VERSION ""

NS_ :

BS_:

BU_:

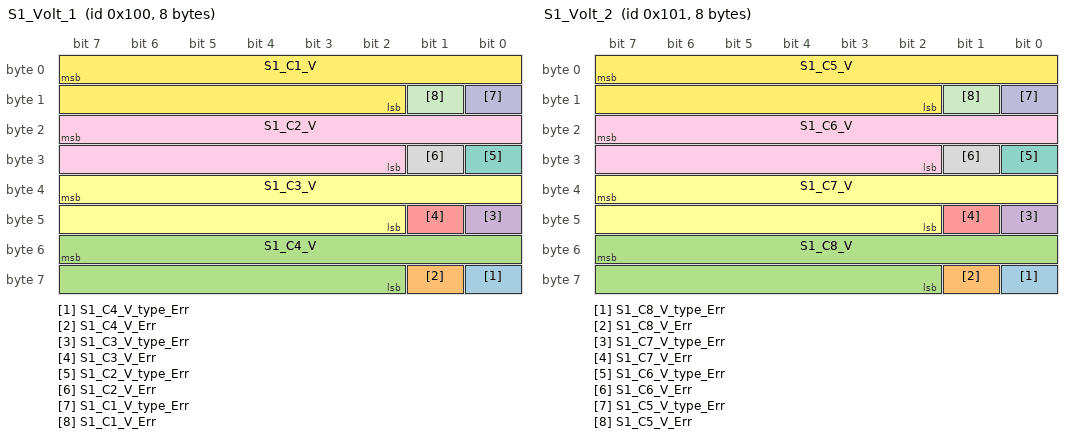
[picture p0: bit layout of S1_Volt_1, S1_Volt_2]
BO_ 256 S1_Volt_1: 8 Master
 SG_ S1_C4_V_type_Err : 56|1@0+ (1,0) [0.0|1.0] "" Vector__XXX
 SG_ S1_C4_V_Err : 57|1@0+ (1,0) [0.0|1.0] "" Vector__XXX
 SG_ S1_C4_V : 55|14@0+ (0.00015,2.3) [2.3|4.75745] "V" Vector__XXX
 SG_ S1_C3_V_type_Err : 40|1@0+ (1,0) [0.0|1.0] "" Vector__XXX
 SG_ S1_C3_V_Err : 41|1@0+ (1,0) [0.0|1.0] "" Vector__XXX
 SG_ S1_C3_V : 39|14@0+ (0.00015,2.3) [2.3|4.75745] "V" Vector__XXX
 SG_ S1_C2_V_type_Err : 24|1@0+ (1,0) [0.0|1.0] "" Vector__XXX
 SG_ S1_C2_V_Err : 25|1@0+ (1,0) [0.0|1.0] "" Vector__XXX
 SG_ S1_C2_V : 23|14@0+ (0.00015,2.3) [2.3|4.75745] "V" Vector__XXX
 SG_ S1_C1_V_type_Err : 8|1@0+ (1,0) [0.0|1.0] "" Vector__XXX
 SG_ S1_C1_V_Err : 9|1@0+ (1,0) [0.0|1.0] "" Vector__XXX
 SG_ S1_C1_V : 7|14@0+ (0.00015,2.3) [2.3|4.75745] "V" Vector__XXX

BO_ 257 S1_Volt_2: 8 Master
 SG_ S1_C8_V_type_Err : 56|1@0+ (1,0) [0.0|1.0] "" Vector__XXX
 SG_ S1_C8_V_Err : 57|1@0+ (1,0) [0.0|1.0] "" Vector__XXX
 SG_ S1_C8_V : 55|14@0+ (0.00015,2.3) [2.3|4.75745] "V" Vector__XXX
 SG_ S1_C7_V_type_Err : 40|1@0+ (1,0) [0.0|1.0] "" Vector__XXX
 SG_ S1_C7_V_Err : 41|1@0+ (1,0) [0.0|1.0] "" Vector__XXX
 SG_ S1_C7_V : 39|14@0+ (0.00015,2.3) [2.3|4.75745] "V" Vector__XXX
 SG_ S1_C6_V_type_Err : 24|1@0+ (1,0) [0.0|1.0] "" Vector__XXX
 SG_ S1_C6_V_Err : 25|1@0+ (1,0) [0.0|1.0] "" Vector__XXX
 SG_ S1_C6_V : 23|14@0+ (0.00015,2.3) [2.3|4.75745] "V" Vector__XXX
 SG_ S1_C5_V_type_Err : 8|1@0+ (1,0) [0.0|1.0] "" Vector__XXX
 SG_ S1_C5_V_Err : 9|1@0+ (1,0) [0.0|1.0] "" Vector__XXX
 SG_ S1_C5_V : 7|14@0+ (0.00015,2.3) [2.3|4.75745] "V" Vector__XXX

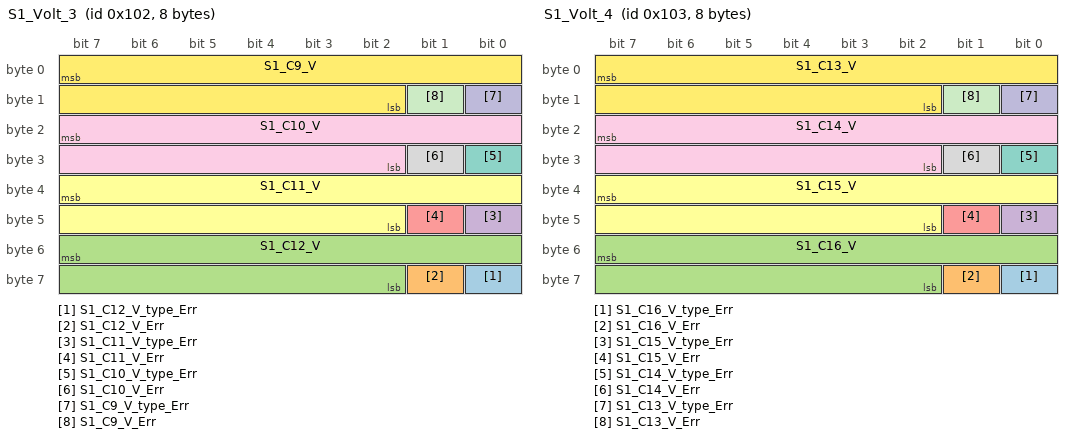
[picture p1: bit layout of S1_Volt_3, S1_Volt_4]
BO_ 258 S1_Volt_3: 8 Master
 SG_ S1_C12_V_type_Err : 56|1@0+ (1,0) [0.0|1.0] "" Vector__XXX
 SG_ S1_C12_V_Err : 57|1@0+ (1,0) [0.0|1.0] "" Vector__XXX
 SG_ S1_C12_V : 55|14@0+ (0.00015,2.3) [2.3|4.75745] "V" Vector__XXX
 SG_ S1_C11_V_type_Err : 40|1@0+ (1,0) [0.0|1.0] "" Vector__XXX
 SG_ S1_C11_V_Err : 41|1@0+ (1,0) [0.0|1.0] "" Vector__XXX
 SG_ S1_C11_V : 39|14@0+ (0.00015,2.3) [2.3|4.75745] "V" Vector__XXX
 SG_ S1_C10_V_type_Err : 24|1@0+ (1,0) [0.0|1.0] "" Vector__XXX
 SG_ S1_C10_V_Err : 25|1@0+ (1,0) [0.0|1.0] "" Vector__XXX
 SG_ S1_C10_V : 23|14@0+ (0.00015,2.3) [2.3|4.75745] "V" Vector__XXX
 SG_ S1_C9_V_type_Err : 8|1@0+ (1,0) [0.0|1.0] "" Vector__XXX
 SG_ S1_C9_V_Err : 9|1@0+ (1,0) [0.0|1.0] "" Vector__XXX
 SG_ S1_C9_V : 7|14@0+ (0.00015,2.3) [2.3|4.75745] "V" Vector__XXX

BO_ 259 S1_Volt_4: 8 Master
 SG_ S1_C16_V_type_Err : 56|1@0+ (1,0) [0.0|1.0] "" Vector__XXX
 SG_ S1_C16_V_Err : 57|1@0+ (1,0) [0.0|1.0] "" Vector__XXX
 SG_ S1_C16_V : 55|14@0+ (0.00015,2.3) [2.3|4.75745] "V" Vector__XXX
 SG_ S1_C15_V_type_Err : 40|1@0+ (1,0) [0.0|1.0] "" Vector__XXX
 SG_ S1_C15_V_Err : 41|1@0+ (1,0) [0.0|1.0] "" Vector__XXX
 SG_ S1_C15_V : 39|14@0+ (0.00015,2.3) [2.3|4.75745] "V" Vector__XXX
 SG_ S1_C14_V_type_Err : 24|1@0+ (1,0) [0.0|1.0] "" Vector__XXX
 SG_ S1_C14_V_Err : 25|1@0+ (1,0) [0.0|1.0] "" Vector__XXX
 SG_ S1_C14_V : 23|14@0+ (0.00015,2.3) [2.3|4.75745] "V" Vector__XXX
 SG_ S1_C13_V_type_Err : 8|1@0+ (1,0) [0.0|1.0] "" Vector__XXX
 SG_ S1_C13_V_Err : 9|1@0+ (1,0) [0.0|1.0] "" Vector__XXX
 SG_ S1_C13_V : 7|14@0+ (0.00015,2.3) [2.3|4.75745] "V" Vector__XXX

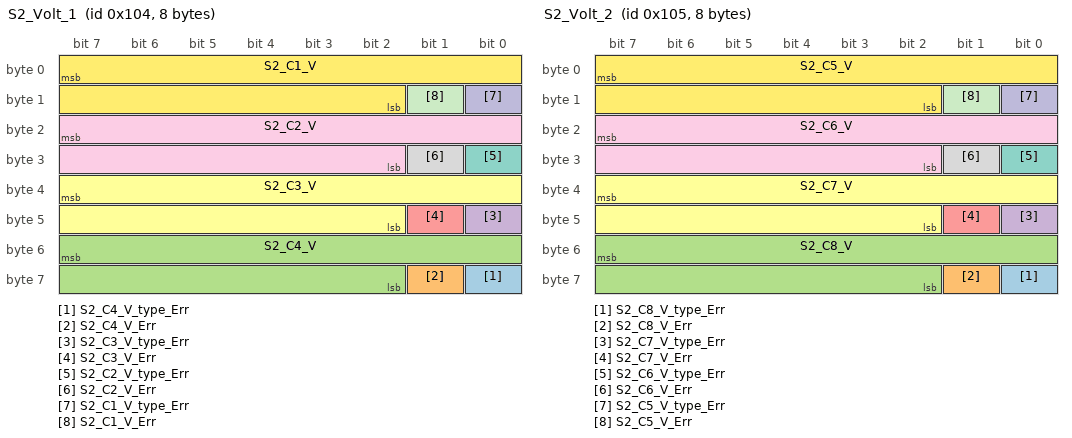
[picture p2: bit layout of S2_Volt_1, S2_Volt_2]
BO_ 260 S2_Volt_1: 8 Master
 SG_ S2_C4_V_type_Err : 56|1@0+ (1,0) [0.0|1.0] "" Vector__XXX
 SG_ S2_C4_V_Err : 57|1@0+ (1,0) [0.0|1.0] "" Vector__XXX
 SG_ S2_C4_V : 55|14@0+ (0.00015,2.3) [2.3|4.75745] "V" Vector__XXX
 SG_ S2_C3_V_type_Err : 40|1@0+ (1,0) [0.0|1.0] "" Vector__XXX
 SG_ S2_C3_V_Err : 41|1@0+ (1,0) [0.0|1.0] "" Vector__XXX
 SG_ S2_C3_V : 39|14@0+ (0.00015,2.3) [2.3|4.75745] "V" Vector__XXX
 SG_ S2_C2_V_type_Err : 24|1@0+ (1,0) [0.0|1.0] "" Vector__XXX
 SG_ S2_C2_V_Err : 25|1@0+ (1,0) [0.0|1.0] "" Vector__XXX
 SG_ S2_C2_V : 23|14@0+ (0.00015,2.3) [2.3|4.75745] "V" Vector__XXX
 SG_ S2_C1_V_type_Err : 8|1@0+ (1,0) [0.0|1.0] "" Vector__XXX
 SG_ S2_C1_V_Err : 9|1@0+ (1,0) [0.0|1.0] "" Vector__XXX
 SG_ S2_C1_V : 7|14@0+ (0.00015,2.3) [2.3|4.75745] "V" Vector__XXX

BO_ 261 S2_Volt_2: 8 Master
 SG_ S2_C8_V_type_Err : 56|1@0+ (1,0) [0.0|1.0] "" Vector__XXX
 SG_ S2_C8_V_Err : 57|1@0+ (1,0) [0.0|1.0] "" Vector__XXX
 SG_ S2_C8_V : 55|14@0+ (0.00015,2.3) [2.3|4.75745] "V" Vector__XXX
 SG_ S2_C7_V_type_Err : 40|1@0+ (1,0) [0.0|1.0] "" Vector__XXX
 SG_ S2_C7_V_Err : 41|1@0+ (1,0) [0.0|1.0] "" Vector__XXX
 SG_ S2_C7_V : 39|14@0+ (0.00015,2.3) [2.3|4.75745] "V" Vector__XXX
 SG_ S2_C6_V_type_Err : 24|1@0+ (1,0) [0.0|1.0] "" Vector__XXX
 SG_ S2_C6_V_Err : 25|1@0+ (1,0) [0.0|1.0] "" Vector__XXX
 SG_ S2_C6_V : 23|14@0+ (0.00015,2.3) [2.3|4.75745] "V" Vector__XXX
 SG_ S2_C5_V_type_Err : 8|1@0+ (1,0) [0.0|1.0] "" Vector__XXX
 SG_ S2_C5_V_Err : 9|1@0+ (1,0) [0.0|1.0] "" Vector__XXX
 SG_ S2_C5_V : 7|14@0+ (0.00015,2.3) [2.3|4.75745] "V" Vector__XXX

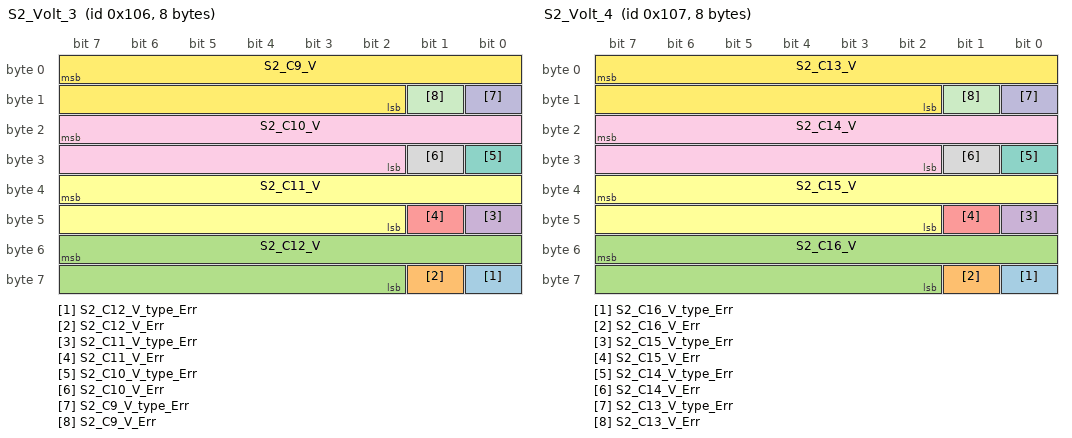
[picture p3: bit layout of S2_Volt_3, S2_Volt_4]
BO_ 262 S2_Volt_3: 8 Master
 SG_ S2_C12_V_type_Err : 56|1@0+ (1,0) [0.0|1.0] "" Vector__XXX
 SG_ S2_C12_V_Err : 57|1@0+ (1,0) [0.0|1.0] "" Vector__XXX
 SG_ S2_C12_V : 55|14@0+ (0.00015,2.3) [2.3|4.75745] "V" Vector__XXX
 SG_ S2_C11_V_type_Err : 40|1@0+ (1,0) [0.0|1.0] "" Vector__XXX
 SG_ S2_C11_V_Err : 41|1@0+ (1,0) [0.0|1.0] "" Vector__XXX
 SG_ S2_C11_V : 39|14@0+ (0.00015,2.3) [2.3|4.75745] "V" Vector__XXX
 SG_ S2_C10_V_type_Err : 24|1@0+ (1,0) [0.0|1.0] "" Vector__XXX
 SG_ S2_C10_V_Err : 25|1@0+ (1,0) [0.0|1.0] "" Vector__XXX
 SG_ S2_C10_V : 23|14@0+ (0.00015,2.3) [2.3|4.75745] "V" Vector__XXX
 SG_ S2_C9_V_type_Err : 8|1@0+ (1,0) [0.0|1.0] "" Vector__XXX
 SG_ S2_C9_V_Err : 9|1@0+ (1,0) [0.0|1.0] "" Vector__XXX
 SG_ S2_C9_V : 7|14@0+ (0.00015,2.3) [2.3|4.75745] "V" Vector__XXX

BO_ 263 S2_Volt_4: 8 Master
 SG_ S2_C16_V_type_Err : 56|1@0+ (1,0) [0.0|1.0] "" Vector__XXX
 SG_ S2_C16_V_Err : 57|1@0+ (1,0) [0.0|1.0] "" Vector__XXX
 SG_ S2_C16_V : 55|14@0+ (0.00015,2.3) [2.3|4.75745] "V" Vector__XXX
 SG_ S2_C15_V_type_Err : 40|1@0+ (1,0) [0.0|1.0] "" Vector__XXX
 SG_ S2_C15_V_Err : 41|1@0+ (1,0) [0.0|1.0] "" Vector__XXX
 SG_ S2_C15_V : 39|14@0+ (0.00015,2.3) [2.3|4.75745] "V" Vector__XXX
 SG_ S2_C14_V_type_Err : 24|1@0+ (1,0) [0.0|1.0] "" Vector__XXX
 SG_ S2_C14_V_Err : 25|1@0+ (1,0) [0.0|1.0] "" Vector__XXX
 SG_ S2_C14_V : 23|14@0+ (0.00015,2.3) [2.3|4.75745] "V" Vector__XXX
 SG_ S2_C13_V_type_Err : 8|1@0+ (1,0) [0.0|1.0] "" Vector__XXX
 SG_ S2_C13_V_Err : 9|1@0+ (1,0) [0.0|1.0] "" Vector__XXX
 SG_ S2_C13_V : 7|14@0+ (0.00015,2.3) [2.3|4.75745] "V" Vector__XXX

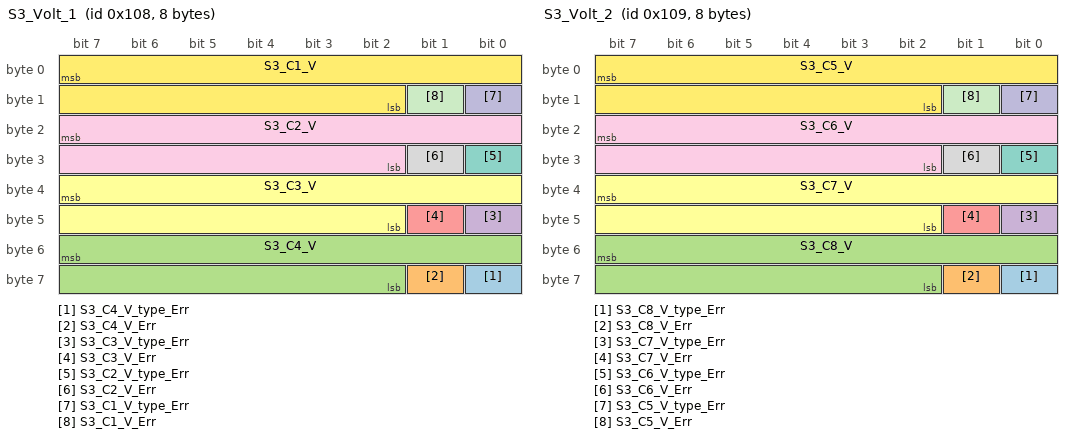
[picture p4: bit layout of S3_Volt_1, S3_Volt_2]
BO_ 264 S3_Volt_1: 8 Master
 SG_ S3_C4_V_type_Err : 56|1@0+ (1,0) [0.0|1.0] "" Vector__XXX
 SG_ S3_C4_V_Err : 57|1@0+ (1,0) [0.0|1.0] "" Vector__XXX
 SG_ S3_C4_V : 55|14@0+ (0.00015,2.3) [2.3|4.75745] "V" Vector__XXX
 SG_ S3_C3_V_type_Err : 40|1@0+ (1,0) [0.0|1.0] "" Vector__XXX
 SG_ S3_C3_V_Err : 41|1@0+ (1,0) [0.0|1.0] "" Vector__XXX
 SG_ S3_C3_V : 39|14@0+ (0.00015,2.3) [2.3|4.75745] "V" Vector__XXX
 SG_ S3_C2_V_type_Err : 24|1@0+ (1,0) [0.0|1.0] "" Vector__XXX
 SG_ S3_C2_V_Err : 25|1@0+ (1,0) [0.0|1.0] "" Vector__XXX
 SG_ S3_C2_V : 23|14@0+ (0.00015,2.3) [2.3|4.75745] "V" Vector__XXX
 SG_ S3_C1_V_type_Err : 8|1@0+ (1,0) [0.0|1.0] "" Vector__XXX
 SG_ S3_C1_V_Err : 9|1@0+ (1,0) [0.0|1.0] "" Vector__XXX
 SG_ S3_C1_V : 7|14@0+ (0.00015,2.3) [2.3|4.75745] "V" Vector__XXX

BO_ 265 S3_Volt_2: 8 Master
 SG_ S3_C8_V_type_Err : 56|1@0+ (1,0) [0.0|1.0] "" Vector__XXX
 SG_ S3_C8_V_Err : 57|1@0+ (1,0) [0.0|1.0] "" Vector__XXX
 SG_ S3_C8_V : 55|14@0+ (0.00015,2.3) [2.3|4.75745] "V" Vector__XXX
 SG_ S3_C7_V_type_Err : 40|1@0+ (1,0) [0.0|1.0] "" Vector__XXX
 SG_ S3_C7_V_Err : 41|1@0+ (1,0) [0.0|1.0] "" Vector__XXX
 SG_ S3_C7_V : 39|14@0+ (0.00015,2.3) [2.3|4.75745] "V" Vector__XXX
 SG_ S3_C6_V_type_Err : 24|1@0+ (1,0) [0.0|1.0] "" Vector__XXX
 SG_ S3_C6_V_Err : 25|1@0+ (1,0) [0.0|1.0] "" Vector__XXX
 SG_ S3_C6_V : 23|14@0+ (0.00015,2.3) [2.3|4.75745] "V" Vector__XXX
 SG_ S3_C5_V_type_Err : 8|1@0+ (1,0) [0.0|1.0] "" Vector__XXX
 SG_ S3_C5_V_Err : 9|1@0+ (1,0) [0.0|1.0] "" Vector__XXX
 SG_ S3_C5_V : 7|14@0+ (0.00015,2.3) [2.3|4.75745] "V" Vector__XXX

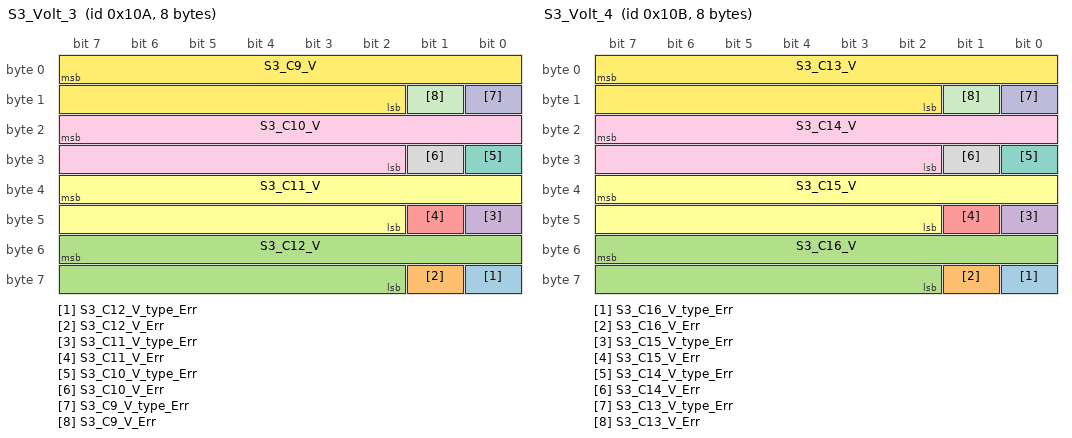
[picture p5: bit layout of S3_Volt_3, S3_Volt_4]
BO_ 266 S3_Volt_3: 8 Master
 SG_ S3_C12_V_type_Err : 56|1@0+ (1,0) [0.0|1.0] "" Vector__XXX
 SG_ S3_C12_V_Err : 57|1@0+ (1,0) [0.0|1.0] "" Vector__XXX
 SG_ S3_C12_V : 55|14@0+ (0.00015,2.3) [2.3|4.75745] "V" Vector__XXX
 SG_ S3_C11_V_type_Err : 40|1@0+ (1,0) [0.0|1.0] "" Vector__XXX
 SG_ S3_C11_V_Err : 41|1@0+ (1,0) [0.0|1.0] "" Vector__XXX
 SG_ S3_C11_V : 39|14@0+ (0.00015,2.3) [2.3|4.75745] "V" Vector__XXX
 SG_ S3_C10_V_type_Err : 24|1@0+ (1,0) [0.0|1.0] "" Vector__XXX
 SG_ S3_C10_V_Err : 25|1@0+ (1,0) [0.0|1.0] "" Vector__XXX
 SG_ S3_C10_V : 23|14@0+ (0.00015,2.3) [2.3|4.75745] "V" Vector__XXX
 SG_ S3_C9_V_type_Err : 8|1@0+ (1,0) [0.0|1.0] "" Vector__XXX
 SG_ S3_C9_V_Err : 9|1@0+ (1,0) [0.0|1.0] "" Vector__XXX
 SG_ S3_C9_V : 7|14@0+ (0.00015,2.3) [2.3|4.75745] "V" Vector__XXX

BO_ 267 S3_Volt_4: 8 Master
 SG_ S3_C16_V_type_Err : 56|1@0+ (1,0) [0.0|1.0] "" Vector__XXX
 SG_ S3_C16_V_Err : 57|1@0+ (1,0) [0.0|1.0] "" Vector__XXX
 SG_ S3_C16_V : 55|14@0+ (0.00015,2.3) [2.3|4.75745] "V" Vector__XXX
 SG_ S3_C15_V_type_Err : 40|1@0+ (1,0) [0.0|1.0] "" Vector__XXX
 SG_ S3_C15_V_Err : 41|1@0+ (1,0) [0.0|1.0] "" Vector__XXX
 SG_ S3_C15_V : 39|14@0+ (0.00015,2.3) [2.3|4.75745] "V" Vector__XXX
 SG_ S3_C14_V_type_Err : 24|1@0+ (1,0) [0.0|1.0] "" Vector__XXX
 SG_ S3_C14_V_Err : 25|1@0+ (1,0) [0.0|1.0] "" Vector__XXX
 SG_ S3_C14_V : 23|14@0+ (0.00015,2.3) [2.3|4.75745] "V" Vector__XXX
 SG_ S3_C13_V_type_Err : 8|1@0+ (1,0) [0.0|1.0] "" Vector__XXX
 SG_ S3_C13_V_Err : 9|1@0+ (1,0) [0.0|1.0] "" Vector__XXX
 SG_ S3_C13_V : 7|14@0+ (0.00015,2.3) [2.3|4.75745] "V" Vector__XXX

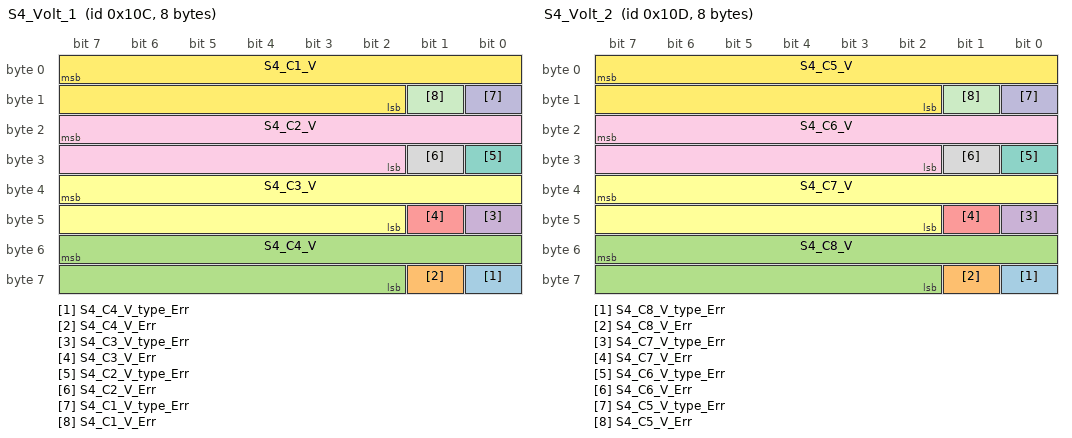
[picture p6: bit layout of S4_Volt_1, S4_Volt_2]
BO_ 268 S4_Volt_1: 8 Master
 SG_ S4_C4_V_type_Err : 56|1@0+ (1,0) [0.0|1.0] "" Vector__XXX
 SG_ S4_C4_V_Err : 57|1@0+ (1,0) [0.0|1.0] "" Vector__XXX
 SG_ S4_C4_V : 55|14@0+ (0.00015,2.3) [2.3|4.75745] "V" Vector__XXX
 SG_ S4_C3_V_type_Err : 40|1@0+ (1,0) [0.0|1.0] "" Vector__XXX
 SG_ S4_C3_V_Err : 41|1@0+ (1,0) [0.0|1.0] "" Vector__XXX
 SG_ S4_C3_V : 39|14@0+ (0.00015,2.3) [2.3|4.75745] "V" Vector__XXX
 SG_ S4_C2_V_type_Err : 24|1@0+ (1,0) [0.0|1.0] "" Vector__XXX
 SG_ S4_C2_V_Err : 25|1@0+ (1,0) [0.0|1.0] "" Vector__XXX
 SG_ S4_C2_V : 23|14@0+ (0.00015,2.3) [2.3|4.75745] "V" Vector__XXX
 SG_ S4_C1_V_type_Err : 8|1@0+ (1,0) [0.0|1.0] "" Vector__XXX
 SG_ S4_C1_V_Err : 9|1@0+ (1,0) [0.0|1.0] "" Vector__XXX
 SG_ S4_C1_V : 7|14@0+ (0.00015,2.3) [2.3|4.75745] "V" Vector__XXX

BO_ 269 S4_Volt_2: 8 Master
 SG_ S4_C8_V_type_Err : 56|1@0+ (1,0) [0.0|1.0] "" Vector__XXX
 SG_ S4_C8_V_Err : 57|1@0+ (1,0) [0.0|1.0] "" Vector__XXX
 SG_ S4_C8_V : 55|14@0+ (0.00015,2.3) [2.3|4.75745] "V" Vector__XXX
 SG_ S4_C7_V_type_Err : 40|1@0+ (1,0) [0.0|1.0] "" Vector__XXX
 SG_ S4_C7_V_Err : 41|1@0+ (1,0) [0.0|1.0] "" Vector__XXX
 SG_ S4_C7_V : 39|14@0+ (0.00015,2.3) [2.3|4.75745] "V" Vector__XXX
 SG_ S4_C6_V_type_Err : 24|1@0+ (1,0) [0.0|1.0] "" Vector__XXX
 SG_ S4_C6_V_Err : 25|1@0+ (1,0) [0.0|1.0] "" Vector__XXX
 SG_ S4_C6_V : 23|14@0+ (0.00015,2.3) [2.3|4.75745] "V" Vector__XXX
 SG_ S4_C5_V_type_Err : 8|1@0+ (1,0) [0.0|1.0] "" Vector__XXX
 SG_ S4_C5_V_Err : 9|1@0+ (1,0) [0.0|1.0] "" Vector__XXX
 SG_ S4_C5_V : 7|14@0+ (0.00015,2.3) [2.3|4.75745] "V" Vector__XXX

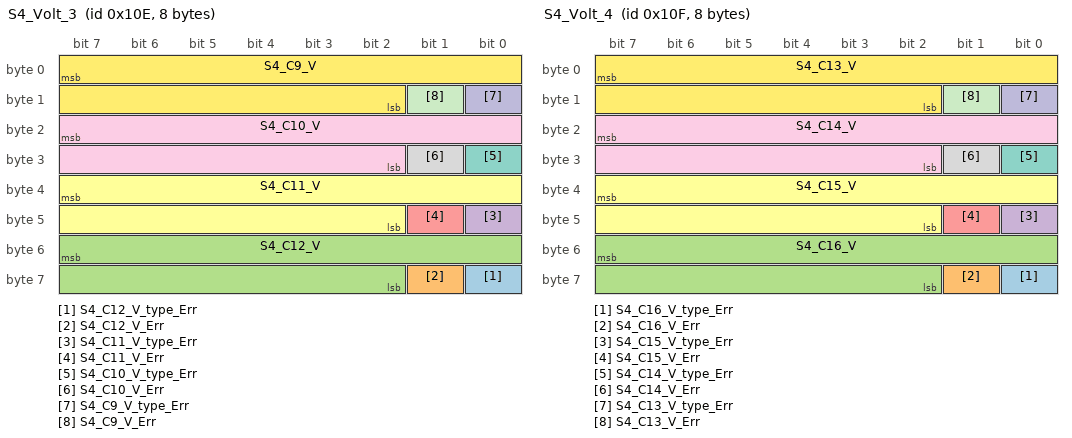
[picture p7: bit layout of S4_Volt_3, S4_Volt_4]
BO_ 270 S4_Volt_3: 8 Master
 SG_ S4_C12_V_type_Err : 56|1@0+ (1,0) [0.0|1.0] "" Vector__XXX
 SG_ S4_C12_V_Err : 57|1@0+ (1,0) [0.0|1.0] "" Vector__XXX
 SG_ S4_C12_V : 55|14@0+ (0.00015,2.3) [2.3|4.75745] "V" Vector__XXX
 SG_ S4_C11_V_type_Err : 40|1@0+ (1,0) [0.0|1.0] "" Vector__XXX
 SG_ S4_C11_V_Err : 41|1@0+ (1,0) [0.0|1.0] "" Vector__XXX
 SG_ S4_C11_V : 39|14@0+ (0.00015,2.3) [2.3|4.75745] "V" Vector__XXX
 SG_ S4_C10_V_type_Err : 24|1@0+ (1,0) [0.0|1.0] "" Vector__XXX
 SG_ S4_C10_V_Err : 25|1@0+ (1,0) [0.0|1.0] "" Vector__XXX
 SG_ S4_C10_V : 23|14@0+ (0.00015,2.3) [2.3|4.75745] "V" Vector__XXX
 SG_ S4_C9_V_type_Err : 8|1@0+ (1,0) [0.0|1.0] "" Vector__XXX
 SG_ S4_C9_V_Err : 9|1@0+ (1,0) [0.0|1.0] "" Vector__XXX
 SG_ S4_C9_V : 7|14@0+ (0.00015,2.3) [2.3|4.75745] "V" Vector__XXX

BO_ 271 S4_Volt_4: 8 Master
 SG_ S4_C16_V_type_Err : 56|1@0+ (1,0) [0.0|1.0] "" Vector__XXX
 SG_ S4_C16_V_Err : 57|1@0+ (1,0) [0.0|1.0] "" Vector__XXX
 SG_ S4_C16_V : 55|14@0+ (0.00015,2.3) [2.3|4.75745] "V" Vector__XXX
 SG_ S4_C15_V_type_Err : 40|1@0+ (1,0) [0.0|1.0] "" Vector__XXX
 SG_ S4_C15_V_Err : 41|1@0+ (1,0) [0.0|1.0] "" Vector__XXX
 SG_ S4_C15_V : 39|14@0+ (0.00015,2.3) [2.3|4.75745] "V" Vector__XXX
 SG_ S4_C14_V_type_Err : 24|1@0+ (1,0) [0.0|1.0] "" Vector__XXX
 SG_ S4_C14_V_Err : 25|1@0+ (1,0) [0.0|1.0] "" Vector__XXX
 SG_ S4_C14_V : 23|14@0+ (0.00015,2.3) [2.3|4.75745] "V" Vector__XXX
 SG_ S4_C13_V_type_Err : 8|1@0+ (1,0) [0.0|1.0] "" Vector__XXX
 SG_ S4_C13_V_Err : 9|1@0+ (1,0) [0.0|1.0] "" Vector__XXX
 SG_ S4_C13_V : 7|14@0+ (0.00015,2.3) [2.3|4.75745] "V" Vector__XXX

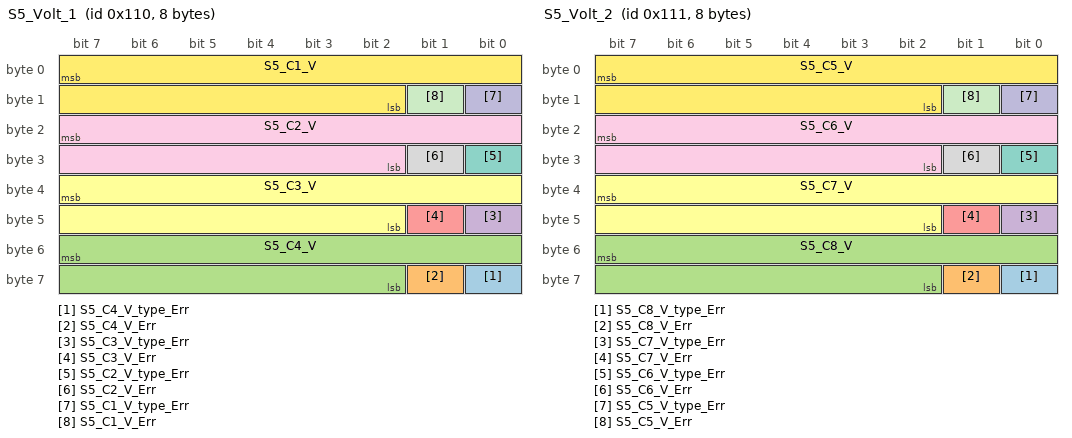
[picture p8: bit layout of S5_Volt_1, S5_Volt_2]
BO_ 272 S5_Volt_1: 8 Master
 SG_ S5_C4_V_type_Err : 56|1@0+ (1,0) [0.0|1.0] "" Vector__XXX
 SG_ S5_C4_V_Err : 57|1@0+ (1,0) [0.0|1.0] "" Vector__XXX
 SG_ S5_C4_V : 55|14@0+ (0.00015,2.3) [2.3|4.75745] "V" Vector__XXX
 SG_ S5_C3_V_type_Err : 40|1@0+ (1,0) [0.0|1.0] "" Vector__XXX
 SG_ S5_C3_V_Err : 41|1@0+ (1,0) [0.0|1.0] "" Vector__XXX
 SG_ S5_C3_V : 39|14@0+ (0.00015,2.3) [2.3|4.75745] "V" Vector__XXX
 SG_ S5_C2_V_type_Err : 24|1@0+ (1,0) [0.0|1.0] "" Vector__XXX
 SG_ S5_C2_V_Err : 25|1@0+ (1,0) [0.0|1.0] "" Vector__XXX
 SG_ S5_C2_V : 23|14@0+ (0.00015,2.3) [2.3|4.75745] "V" Vector__XXX
 SG_ S5_C1_V_type_Err : 8|1@0+ (1,0) [0.0|1.0] "" Vector__XXX
 SG_ S5_C1_V_Err : 9|1@0+ (1,0) [0.0|1.0] "" Vector__XXX
 SG_ S5_C1_V : 7|14@0+ (0.00015,2.3) [2.3|4.75745] "V" Vector__XXX

BO_ 273 S5_Volt_2: 8 Master
 SG_ S5_C8_V_type_Err : 56|1@0+ (1,0) [0.0|1.0] "" Vector__XXX
 SG_ S5_C8_V_Err : 57|1@0+ (1,0) [0.0|1.0] "" Vector__XXX
 SG_ S5_C8_V : 55|14@0+ (0.00015,2.3) [2.3|4.75745] "V" Vector__XXX
 SG_ S5_C7_V_type_Err : 40|1@0+ (1,0) [0.0|1.0] "" Vector__XXX
 SG_ S5_C7_V_Err : 41|1@0+ (1,0) [0.0|1.0] "" Vector__XXX
 SG_ S5_C7_V : 39|14@0+ (0.00015,2.3) [2.3|4.75745] "V" Vector__XXX
 SG_ S5_C6_V_type_Err : 24|1@0+ (1,0) [0.0|1.0] "" Vector__XXX
 SG_ S5_C6_V_Err : 25|1@0+ (1,0) [0.0|1.0] "" Vector__XXX
 SG_ S5_C6_V : 23|14@0+ (0.00015,2.3) [2.3|4.75745] "V" Vector__XXX
 SG_ S5_C5_V_type_Err : 8|1@0+ (1,0) [0.0|1.0] "" Vector__XXX
 SG_ S5_C5_V_Err : 9|1@0+ (1,0) [0.0|1.0] "" Vector__XXX
 SG_ S5_C5_V : 7|14@0+ (0.00015,2.3) [2.3|4.75745] "V" Vector__XXX

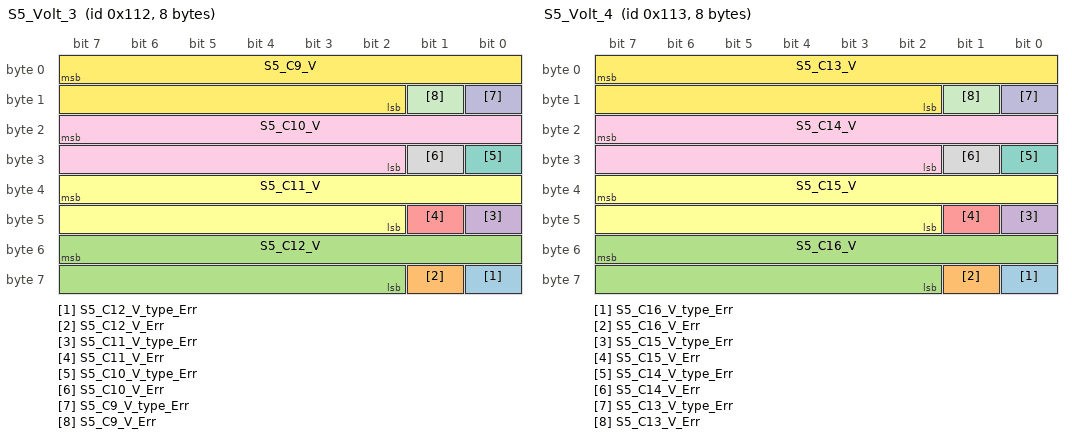
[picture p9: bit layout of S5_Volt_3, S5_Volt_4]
BO_ 274 S5_Volt_3: 8 Master
 SG_ S5_C12_V_type_Err : 56|1@0+ (1,0) [0.0|1.0] "" Vector__XXX
 SG_ S5_C12_V_Err : 57|1@0+ (1,0) [0.0|1.0] "" Vector__XXX
 SG_ S5_C12_V : 55|14@0+ (0.00015,2.3) [2.3|4.75745] "V" Vector__XXX
 SG_ S5_C11_V_type_Err : 40|1@0+ (1,0) [0.0|1.0] "" Vector__XXX
 SG_ S5_C11_V_Err : 41|1@0+ (1,0) [0.0|1.0] "" Vector__XXX
 SG_ S5_C11_V : 39|14@0+ (0.00015,2.3) [2.3|4.75745] "V" Vector__XXX
 SG_ S5_C10_V_type_Err : 24|1@0+ (1,0) [0.0|1.0] "" Vector__XXX
 SG_ S5_C10_V_Err : 25|1@0+ (1,0) [0.0|1.0] "" Vector__XXX
 SG_ S5_C10_V : 23|14@0+ (0.00015,2.3) [2.3|4.75745] "V" Vector__XXX
 SG_ S5_C9_V_type_Err : 8|1@0+ (1,0) [0.0|1.0] "" Vector__XXX
 SG_ S5_C9_V_Err : 9|1@0+ (1,0) [0.0|1.0] "" Vector__XXX
 SG_ S5_C9_V : 7|14@0+ (0.00015,2.3) [2.3|4.75745] "V" Vector__XXX

BO_ 275 S5_Volt_4: 8 Master
 SG_ S5_C16_V_type_Err : 56|1@0+ (1,0) [0.0|1.0] "" Vector__XXX
 SG_ S5_C16_V_Err : 57|1@0+ (1,0) [0.0|1.0] "" Vector__XXX
 SG_ S5_C16_V : 55|14@0+ (0.00015,2.3) [2.3|4.75745] "V" Vector__XXX
 SG_ S5_C15_V_type_Err : 40|1@0+ (1,0) [0.0|1.0] "" Vector__XXX
 SG_ S5_C15_V_Err : 41|1@0+ (1,0) [0.0|1.0] "" Vector__XXX
 SG_ S5_C15_V : 39|14@0+ (0.00015,2.3) [2.3|4.75745] "V" Vector__XXX
 SG_ S5_C14_V_type_Err : 24|1@0+ (1,0) [0.0|1.0] "" Vector__XXX
 SG_ S5_C14_V_Err : 25|1@0+ (1,0) [0.0|1.0] "" Vector__XXX
 SG_ S5_C14_V : 23|14@0+ (0.00015,2.3) [2.3|4.75745] "V" Vector__XXX
 SG_ S5_C13_V_type_Err : 8|1@0+ (1,0) [0.0|1.0] "" Vector__XXX
 SG_ S5_C13_V_Err : 9|1@0+ (1,0) [0.0|1.0] "" Vector__XXX
 SG_ S5_C13_V : 7|14@0+ (0.00015,2.3) [2.3|4.75745] "V" Vector__XXX

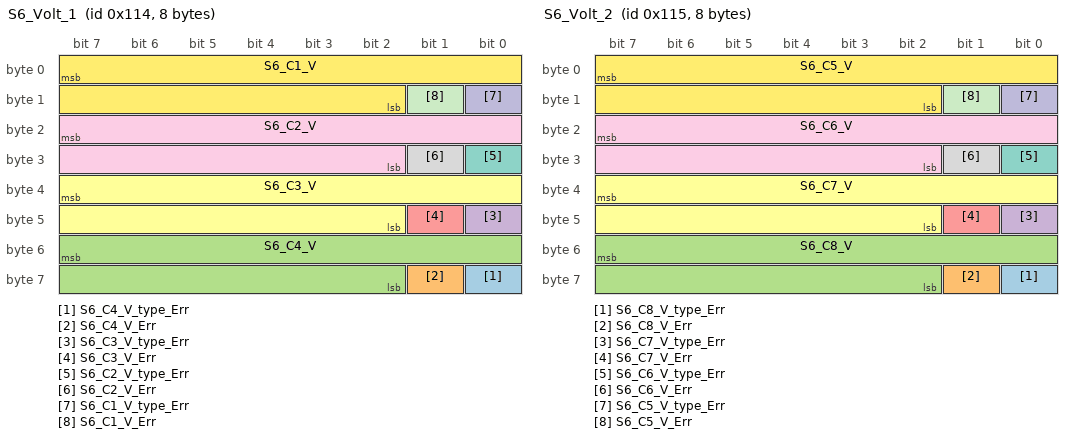
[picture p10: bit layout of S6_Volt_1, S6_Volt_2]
BO_ 276 S6_Volt_1: 8 Master
 SG_ S6_C4_V_type_Err : 56|1@0+ (1,0) [0.0|1.0] "" Vector__XXX
 SG_ S6_C4_V_Err : 57|1@0+ (1,0) [0.0|1.0] "" Vector__XXX
 SG_ S6_C4_V : 55|14@0+ (0.00015,2.3) [2.3|4.75745] "V" Vector__XXX
 SG_ S6_C3_V_type_Err : 40|1@0+ (1,0) [0.0|1.0] "" Vector__XXX
 SG_ S6_C3_V_Err : 41|1@0+ (1,0) [0.0|1.0] "" Vector__XXX
 SG_ S6_C3_V : 39|14@0+ (0.00015,2.3) [2.3|4.75745] "V" Vector__XXX
 SG_ S6_C2_V_type_Err : 24|1@0+ (1,0) [0.0|1.0] "" Vector__XXX
 SG_ S6_C2_V_Err : 25|1@0+ (1,0) [0.0|1.0] "" Vector__XXX
 SG_ S6_C2_V : 23|14@0+ (0.00015,2.3) [2.3|4.75745] "V" Vector__XXX
 SG_ S6_C1_V_type_Err : 8|1@0+ (1,0) [0.0|1.0] "" Vector__XXX
 SG_ S6_C1_V_Err : 9|1@0+ (1,0) [0.0|1.0] "" Vector__XXX
 SG_ S6_C1_V : 7|14@0+ (0.00015,2.3) [2.3|4.75745] "V" Vector__XXX

BO_ 277 S6_Volt_2: 8 Master
 SG_ S6_C8_V_type_Err : 56|1@0+ (1,0) [0.0|1.0] "" Vector__XXX
 SG_ S6_C8_V_Err : 57|1@0+ (1,0) [0.0|1.0] "" Vector__XXX
 SG_ S6_C8_V : 55|14@0+ (0.00015,2.3) [2.3|4.75745] "V" Vector__XXX
 SG_ S6_C7_V_type_Err : 40|1@0+ (1,0) [0.0|1.0] "" Vector__XXX
 SG_ S6_C7_V_Err : 41|1@0+ (1,0) [0.0|1.0] "" Vector__XXX
 SG_ S6_C7_V : 39|14@0+ (0.00015,2.3) [2.3|4.75745] "V" Vector__XXX
 SG_ S6_C6_V_type_Err : 24|1@0+ (1,0) [0.0|1.0] "" Vector__XXX
 SG_ S6_C6_V_Err : 25|1@0+ (1,0) [0.0|1.0] "" Vector__XXX
 SG_ S6_C6_V : 23|14@0+ (0.00015,2.3) [2.3|4.75745] "V" Vector__XXX
 SG_ S6_C5_V_type_Err : 8|1@0+ (1,0) [0.0|1.0] "" Vector__XXX
 SG_ S6_C5_V_Err : 9|1@0+ (1,0) [0.0|1.0] "" Vector__XXX
 SG_ S6_C5_V : 7|14@0+ (0.00015,2.3) [2.3|4.75745] "V" Vector__XXX

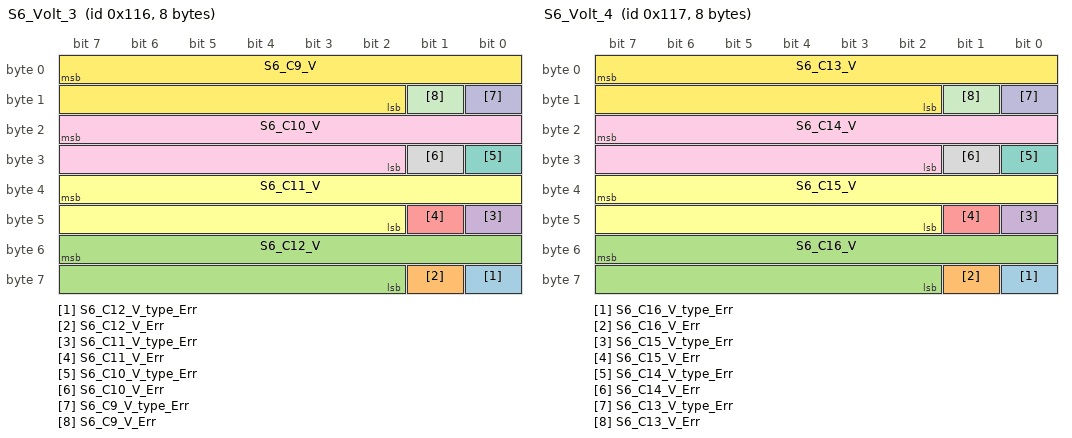
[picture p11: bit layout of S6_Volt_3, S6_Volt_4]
BO_ 278 S6_Volt_3: 8 Master
 SG_ S6_C12_V_type_Err : 56|1@0+ (1,0) [0.0|1.0] "" Vector__XXX
 SG_ S6_C12_V_Err : 57|1@0+ (1,0) [0.0|1.0] "" Vector__XXX
 SG_ S6_C12_V : 55|14@0+ (0.00015,2.3) [2.3|4.75745] "V" Vector__XXX
 SG_ S6_C11_V_type_Err : 40|1@0+ (1,0) [0.0|1.0] "" Vector__XXX
 SG_ S6_C11_V_Err : 41|1@0+ (1,0) [0.0|1.0] "" Vector__XXX
 SG_ S6_C11_V : 39|14@0+ (0.00015,2.3) [2.3|4.75745] "V" Vector__XXX
 SG_ S6_C10_V_type_Err : 24|1@0+ (1,0) [0.0|1.0] "" Vector__XXX
 SG_ S6_C10_V_Err : 25|1@0+ (1,0) [0.0|1.0] "" Vector__XXX
 SG_ S6_C10_V : 23|14@0+ (0.00015,2.3) [2.3|4.75745] "V" Vector__XXX
 SG_ S6_C9_V_type_Err : 8|1@0+ (1,0) [0.0|1.0] "" Vector__XXX
 SG_ S6_C9_V_Err : 9|1@0+ (1,0) [0.0|1.0] "" Vector__XXX
 SG_ S6_C9_V : 7|14@0+ (0.00015,2.3) [2.3|4.75745] "V" Vector__XXX

BO_ 279 S6_Volt_4: 8 Master
 SG_ S6_C16_V_type_Err : 56|1@0+ (1,0) [0.0|1.0] "" Vector__XXX
 SG_ S6_C16_V_Err : 57|1@0+ (1,0) [0.0|1.0] "" Vector__XXX
 SG_ S6_C16_V : 55|14@0+ (0.00015,2.3) [2.3|4.75745] "V" Vector__XXX
 SG_ S6_C15_V_type_Err : 40|1@0+ (1,0) [0.0|1.0] "" Vector__XXX
 SG_ S6_C15_V_Err : 41|1@0+ (1,0) [0.0|1.0] "" Vector__XXX
 SG_ S6_C15_V : 39|14@0+ (0.00015,2.3) [2.3|4.75745] "V" Vector__XXX
 SG_ S6_C14_V_type_Err : 24|1@0+ (1,0) [0.0|1.0] "" Vector__XXX
 SG_ S6_C14_V_Err : 25|1@0+ (1,0) [0.0|1.0] "" Vector__XXX
 SG_ S6_C14_V : 23|14@0+ (0.00015,2.3) [2.3|4.75745] "V" Vector__XXX
 SG_ S6_C13_V_type_Err : 8|1@0+ (1,0) [0.0|1.0] "" Vector__XXX
 SG_ S6_C13_V_Err : 9|1@0+ (1,0) [0.0|1.0] "" Vector__XXX
 SG_ S6_C13_V : 7|14@0+ (0.00015,2.3) [2.3|4.75745] "V" Vector__XXX

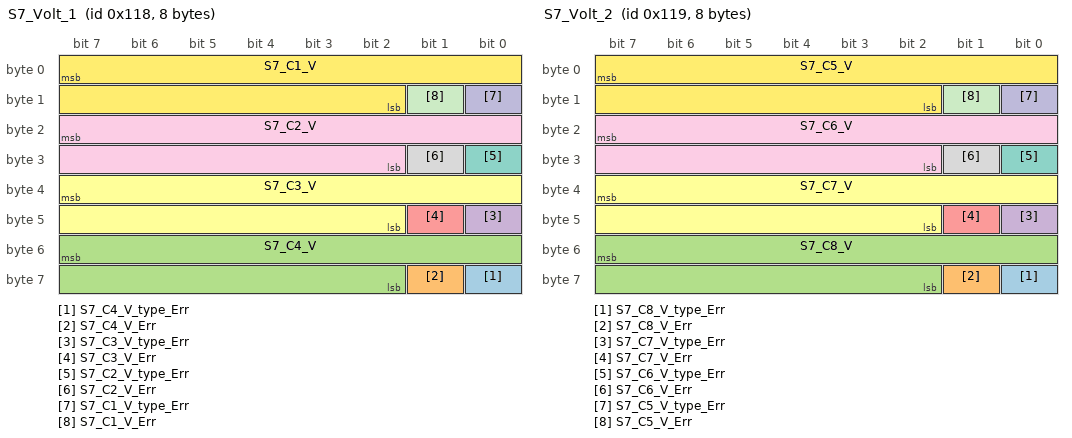
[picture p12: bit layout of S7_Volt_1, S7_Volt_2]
BO_ 280 S7_Volt_1: 8 Master
 SG_ S7_C4_V_type_Err : 56|1@0+ (1,0) [0.0|1.0] "" Vector__XXX
 SG_ S7_C4_V_Err : 57|1@0+ (1,0) [0.0|1.0] "" Vector__XXX
 SG_ S7_C4_V : 55|14@0+ (0.00015,2.3) [2.3|4.75745] "V" Vector__XXX
 SG_ S7_C3_V_type_Err : 40|1@0+ (1,0) [0.0|1.0] "" Vector__XXX
 SG_ S7_C3_V_Err : 41|1@0+ (1,0) [0.0|1.0] "" Vector__XXX
 SG_ S7_C3_V : 39|14@0+ (0.00015,2.3) [2.3|4.75745] "V" Vector__XXX
 SG_ S7_C2_V_type_Err : 24|1@0+ (1,0) [0.0|1.0] "" Vector__XXX
 SG_ S7_C2_V_Err : 25|1@0+ (1,0) [0.0|1.0] "" Vector__XXX
 SG_ S7_C2_V : 23|14@0+ (0.00015,2.3) [2.3|4.75745] "V" Vector__XXX
 SG_ S7_C1_V_type_Err : 8|1@0+ (1,0) [0.0|1.0] "" Vector__XXX
 SG_ S7_C1_V_Err : 9|1@0+ (1,0) [0.0|1.0] "" Vector__XXX
 SG_ S7_C1_V : 7|14@0+ (0.00015,2.3) [2.3|4.75745] "V" Vector__XXX

BO_ 281 S7_Volt_2: 8 Master
 SG_ S7_C8_V_type_Err : 56|1@0+ (1,0) [0.0|1.0] "" Vector__XXX
 SG_ S7_C8_V_Err : 57|1@0+ (1,0) [0.0|1.0] "" Vector__XXX
 SG_ S7_C8_V : 55|14@0+ (0.00015,2.3) [2.3|4.75745] "V" Vector__XXX
 SG_ S7_C7_V_type_Err : 40|1@0+ (1,0) [0.0|1.0] "" Vector__XXX
 SG_ S7_C7_V_Err : 41|1@0+ (1,0) [0.0|1.0] "" Vector__XXX
 SG_ S7_C7_V : 39|14@0+ (0.00015,2.3) [2.3|4.75745] "V" Vector__XXX
 SG_ S7_C6_V_type_Err : 24|1@0+ (1,0) [0.0|1.0] "" Vector__XXX
 SG_ S7_C6_V_Err : 25|1@0+ (1,0) [0.0|1.0] "" Vector__XXX
 SG_ S7_C6_V : 23|14@0+ (0.00015,2.3) [2.3|4.75745] "V" Vector__XXX
 SG_ S7_C5_V_type_Err : 8|1@0+ (1,0) [0.0|1.0] "" Vector__XXX
 SG_ S7_C5_V_Err : 9|1@0+ (1,0) [0.0|1.0] "" Vector__XXX
 SG_ S7_C5_V : 7|14@0+ (0.00015,2.3) [2.3|4.75745] "V" Vector__XXX

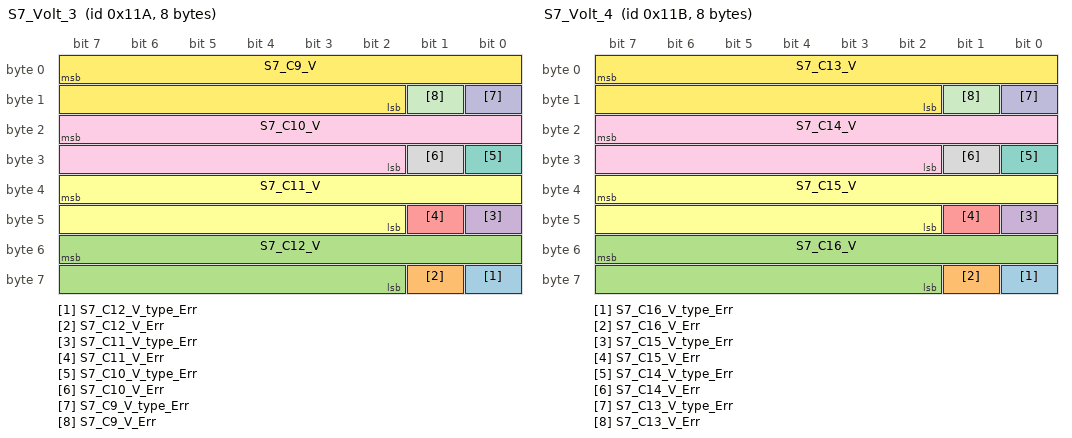
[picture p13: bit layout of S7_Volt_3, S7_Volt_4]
BO_ 282 S7_Volt_3: 8 Master
 SG_ S7_C12_V_type_Err : 56|1@0+ (1,0) [0.0|1.0] "" Vector__XXX
 SG_ S7_C12_V_Err : 57|1@0+ (1,0) [0.0|1.0] "" Vector__XXX
 SG_ S7_C12_V : 55|14@0+ (0.00015,2.3) [2.3|4.75745] "V" Vector__XXX
 SG_ S7_C11_V_type_Err : 40|1@0+ (1,0) [0.0|1.0] "" Vector__XXX
 SG_ S7_C11_V_Err : 41|1@0+ (1,0) [0.0|1.0] "" Vector__XXX
 SG_ S7_C11_V : 39|14@0+ (0.00015,2.3) [2.3|4.75745] "V" Vector__XXX
 SG_ S7_C10_V_type_Err : 24|1@0+ (1,0) [0.0|1.0] "" Vector__XXX
 SG_ S7_C10_V_Err : 25|1@0+ (1,0) [0.0|1.0] "" Vector__XXX
 SG_ S7_C10_V : 23|14@0+ (0.00015,2.3) [2.3|4.75745] "V" Vector__XXX
 SG_ S7_C9_V_type_Err : 8|1@0+ (1,0) [0.0|1.0] "" Vector__XXX
 SG_ S7_C9_V_Err : 9|1@0+ (1,0) [0.0|1.0] "" Vector__XXX
 SG_ S7_C9_V : 7|14@0+ (0.00015,2.3) [2.3|4.75745] "V" Vector__XXX

BO_ 283 S7_Volt_4: 8 Master
 SG_ S7_C16_V_type_Err : 56|1@0+ (1,0) [0.0|1.0] "" Vector__XXX
 SG_ S7_C16_V_Err : 57|1@0+ (1,0) [0.0|1.0] "" Vector__XXX
 SG_ S7_C16_V : 55|14@0+ (0.00015,2.3) [2.3|4.75745] "V" Vector__XXX
 SG_ S7_C15_V_type_Err : 40|1@0+ (1,0) [0.0|1.0] "" Vector__XXX
 SG_ S7_C15_V_Err : 41|1@0+ (1,0) [0.0|1.0] "" Vector__XXX
 SG_ S7_C15_V : 39|14@0+ (0.00015,2.3) [2.3|4.75745] "V" Vector__XXX
 SG_ S7_C14_V_type_Err : 24|1@0+ (1,0) [0.0|1.0] "" Vector__XXX
 SG_ S7_C14_V_Err : 25|1@0+ (1,0) [0.0|1.0] "" Vector__XXX
 SG_ S7_C14_V : 23|14@0+ (0.00015,2.3) [2.3|4.75745] "V" Vector__XXX
 SG_ S7_C13_V_type_Err : 8|1@0+ (1,0) [0.0|1.0] "" Vector__XXX
 SG_ S7_C13_V_Err : 9|1@0+ (1,0) [0.0|1.0] "" Vector__XXX
 SG_ S7_C13_V : 7|14@0+ (0.00015,2.3) [2.3|4.75745] "V" Vector__XXX

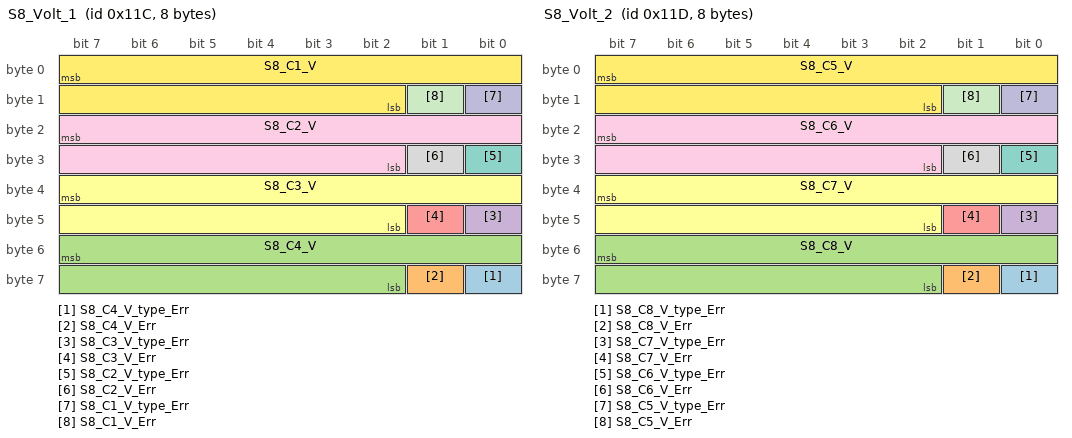
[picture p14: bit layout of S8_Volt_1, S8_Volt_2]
BO_ 284 S8_Volt_1: 8 Master
 SG_ S8_C4_V_type_Err : 56|1@0+ (1,0) [0.0|1.0] "" Vector__XXX
 SG_ S8_C4_V_Err : 57|1@0+ (1,0) [0.0|1.0] "" Vector__XXX
 SG_ S8_C4_V : 55|14@0+ (0.00015,2.3) [2.3|4.75745] "V" Vector__XXX
 SG_ S8_C3_V_type_Err : 40|1@0+ (1,0) [0.0|1.0] "" Vector__XXX
 SG_ S8_C3_V_Err : 41|1@0+ (1,0) [0.0|1.0] "" Vector__XXX
 SG_ S8_C3_V : 39|14@0+ (0.00015,2.3) [2.3|4.75745] "V" Vector__XXX
 SG_ S8_C2_V_type_Err : 24|1@0+ (1,0) [0.0|1.0] "" Vector__XXX
 SG_ S8_C2_V_Err : 25|1@0+ (1,0) [0.0|1.0] "" Vector__XXX
 SG_ S8_C2_V : 23|14@0+ (0.00015,2.3) [2.3|4.75745] "V" Vector__XXX
 SG_ S8_C1_V_type_Err : 8|1@0+ (1,0) [0.0|1.0] "" Vector__XXX
 SG_ S8_C1_V_Err : 9|1@0+ (1,0) [0.0|1.0] "" Vector__XXX
 SG_ S8_C1_V : 7|14@0+ (0.00015,2.3) [2.3|4.75745] "V" Vector__XXX

BO_ 285 S8_Volt_2: 8 Master
 SG_ S8_C8_V_type_Err : 56|1@0+ (1,0) [0.0|1.0] "" Vector__XXX
 SG_ S8_C8_V_Err : 57|1@0+ (1,0) [0.0|1.0] "" Vector__XXX
 SG_ S8_C8_V : 55|14@0+ (0.00015,2.3) [2.3|4.75745] "V" Vector__XXX
 SG_ S8_C7_V_type_Err : 40|1@0+ (1,0) [0.0|1.0] "" Vector__XXX
 SG_ S8_C7_V_Err : 41|1@0+ (1,0) [0.0|1.0] "" Vector__XXX
 SG_ S8_C7_V : 39|14@0+ (0.00015,2.3) [2.3|4.75745] "V" Vector__XXX
 SG_ S8_C6_V_type_Err : 24|1@0+ (1,0) [0.0|1.0] "" Vector__XXX
 SG_ S8_C6_V_Err : 25|1@0+ (1,0) [0.0|1.0] "" Vector__XXX
 SG_ S8_C6_V : 23|14@0+ (0.00015,2.3) [2.3|4.75745] "V" Vector__XXX
 SG_ S8_C5_V_type_Err : 8|1@0+ (1,0) [0.0|1.0] "" Vector__XXX
 SG_ S8_C5_V_Err : 9|1@0+ (1,0) [0.0|1.0] "" Vector__XXX
 SG_ S8_C5_V : 7|14@0+ (0.00015,2.3) [2.3|4.75745] "V" Vector__XXX

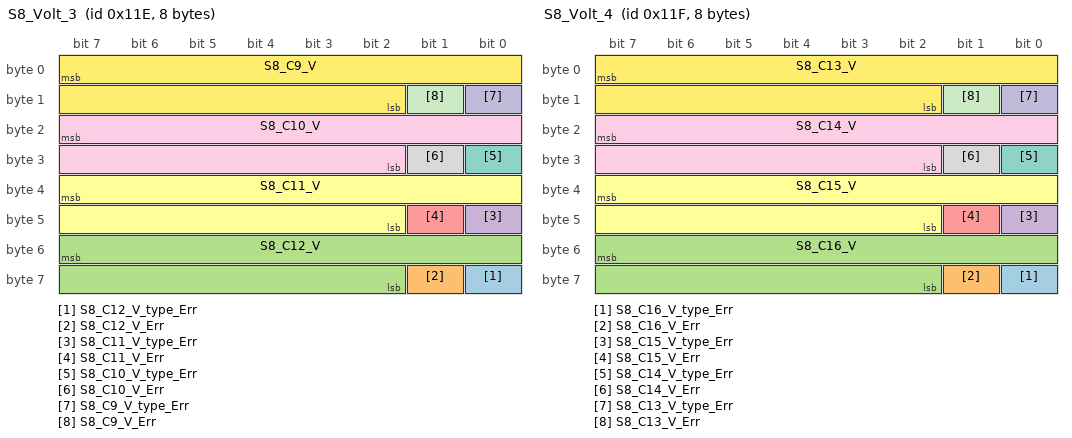
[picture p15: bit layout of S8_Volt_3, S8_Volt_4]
BO_ 286 S8_Volt_3: 8 Master
 SG_ S8_C12_V_type_Err : 56|1@0+ (1,0) [0.0|1.0] "" Vector__XXX
 SG_ S8_C12_V_Err : 57|1@0+ (1,0) [0.0|1.0] "" Vector__XXX
 SG_ S8_C12_V : 55|14@0+ (0.00015,2.3) [2.3|4.75745] "V" Vector__XXX
 SG_ S8_C11_V_type_Err : 40|1@0+ (1,0) [0.0|1.0] "" Vector__XXX
 SG_ S8_C11_V_Err : 41|1@0+ (1,0) [0.0|1.0] "" Vector__XXX
 SG_ S8_C11_V : 39|14@0+ (0.00015,2.3) [2.3|4.75745] "V" Vector__XXX
 SG_ S8_C10_V_type_Err : 24|1@0+ (1,0) [0.0|1.0] "" Vector__XXX
 SG_ S8_C10_V_Err : 25|1@0+ (1,0) [0.0|1.0] "" Vector__XXX
 SG_ S8_C10_V : 23|14@0+ (0.00015,2.3) [2.3|4.75745] "V" Vector__XXX
 SG_ S8_C9_V_type_Err : 8|1@0+ (1,0) [0.0|1.0] "" Vector__XXX
 SG_ S8_C9_V_Err : 9|1@0+ (1,0) [0.0|1.0] "" Vector__XXX
 SG_ S8_C9_V : 7|14@0+ (0.00015,2.3) [2.3|4.75745] "V" Vector__XXX

BO_ 287 S8_Volt_4: 8 Master
 SG_ S8_C16_V_type_Err : 56|1@0+ (1,0) [0.0|1.0] "" Vector__XXX
 SG_ S8_C16_V_Err : 57|1@0+ (1,0) [0.0|1.0] "" Vector__XXX
 SG_ S8_C16_V : 55|14@0+ (0.00015,2.3) [2.3|4.75745] "V" Vector__XXX
 SG_ S8_C15_V_type_Err : 40|1@0+ (1,0) [0.0|1.0] "" Vector__XXX
 SG_ S8_C15_V_Err : 41|1@0+ (1,0) [0.0|1.0] "" Vector__XXX
 SG_ S8_C15_V : 39|14@0+ (0.00015,2.3) [2.3|4.75745] "V" Vector__XXX
 SG_ S8_C14_V_type_Err : 24|1@0+ (1,0) [0.0|1.0] "" Vector__XXX
 SG_ S8_C14_V_Err : 25|1@0+ (1,0) [0.0|1.0] "" Vector__XXX
 SG_ S8_C14_V : 23|14@0+ (0.00015,2.3) [2.3|4.75745] "V" Vector__XXX
 SG_ S8_C13_V_type_Err : 8|1@0+ (1,0) [0.0|1.0] "" Vector__XXX
 SG_ S8_C13_V_Err : 9|1@0+ (1,0) [0.0|1.0] "" Vector__XXX
 SG_ S8_C13_V : 7|14@0+ (0.00015,2.3) [2.3|4.75745] "V" Vector__XXX

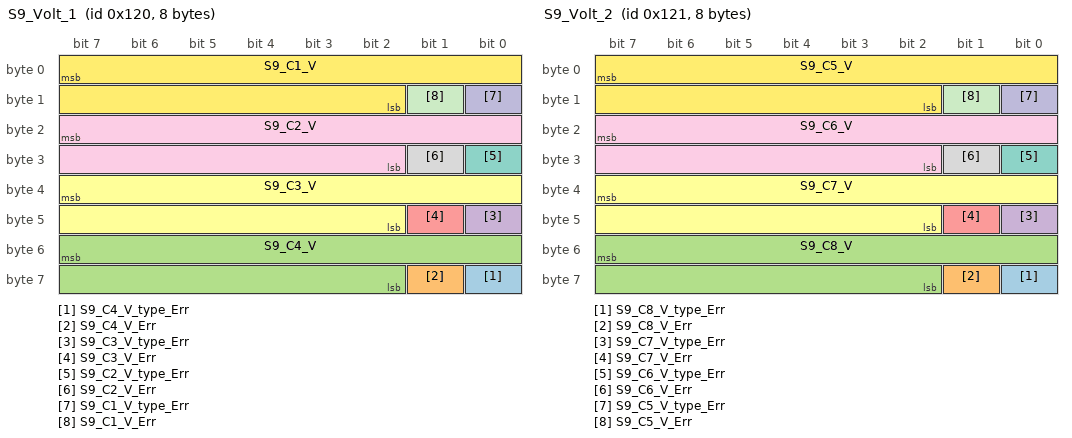
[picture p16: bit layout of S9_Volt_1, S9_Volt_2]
BO_ 288 S9_Volt_1: 8 Master
 SG_ S9_C4_V_type_Err : 56|1@0+ (1,0) [0.0|1.0] "" Vector__XXX
 SG_ S9_C4_V_Err : 57|1@0+ (1,0) [0.0|1.0] "" Vector__XXX
 SG_ S9_C4_V : 55|14@0+ (0.00015,2.3) [2.3|4.75745] "V" Vector__XXX
 SG_ S9_C3_V_type_Err : 40|1@0+ (1,0) [0.0|1.0] "" Vector__XXX
 SG_ S9_C3_V_Err : 41|1@0+ (1,0) [0.0|1.0] "" Vector__XXX
 SG_ S9_C3_V : 39|14@0+ (0.00015,2.3) [2.3|4.75745] "V" Vector__XXX
 SG_ S9_C2_V_type_Err : 24|1@0+ (1,0) [0.0|1.0] "" Vector__XXX
 SG_ S9_C2_V_Err : 25|1@0+ (1,0) [0.0|1.0] "" Vector__XXX
 SG_ S9_C2_V : 23|14@0+ (0.00015,2.3) [2.3|4.75745] "V" Vector__XXX
 SG_ S9_C1_V_type_Err : 8|1@0+ (1,0) [0.0|1.0] "" Vector__XXX
 SG_ S9_C1_V_Err : 9|1@0+ (1,0) [0.0|1.0] "" Vector__XXX
 SG_ S9_C1_V : 7|14@0+ (0.00015,2.3) [2.3|4.75745] "V" Vector__XXX

BO_ 289 S9_Volt_2: 8 Master
 SG_ S9_C8_V_type_Err : 56|1@0+ (1,0) [0.0|1.0] "" Vector__XXX
 SG_ S9_C8_V_Err : 57|1@0+ (1,0) [0.0|1.0] "" Vector__XXX
 SG_ S9_C8_V : 55|14@0+ (0.00015,2.3) [2.3|4.75745] "V" Vector__XXX
 SG_ S9_C7_V_type_Err : 40|1@0+ (1,0) [0.0|1.0] "" Vector__XXX
 SG_ S9_C7_V_Err : 41|1@0+ (1,0) [0.0|1.0] "" Vector__XXX
 SG_ S9_C7_V : 39|14@0+ (0.00015,2.3) [2.3|4.75745] "V" Vector__XXX
 SG_ S9_C6_V_type_Err : 24|1@0+ (1,0) [0.0|1.0] "" Vector__XXX
 SG_ S9_C6_V_Err : 25|1@0+ (1,0) [0.0|1.0] "" Vector__XXX
 SG_ S9_C6_V : 23|14@0+ (0.00015,2.3) [2.3|4.75745] "V" Vector__XXX
 SG_ S9_C5_V_type_Err : 8|1@0+ (1,0) [0.0|1.0] "" Vector__XXX
 SG_ S9_C5_V_Err : 9|1@0+ (1,0) [0.0|1.0] "" Vector__XXX
 SG_ S9_C5_V : 7|14@0+ (0.00015,2.3) [2.3|4.75745] "V" Vector__XXX

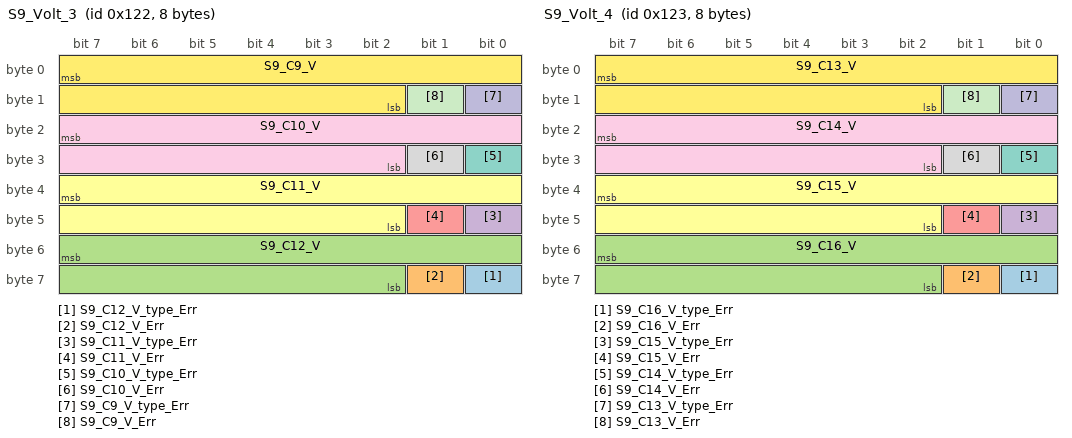
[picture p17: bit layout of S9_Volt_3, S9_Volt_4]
BO_ 290 S9_Volt_3: 8 Master
 SG_ S9_C12_V_type_Err : 56|1@0+ (1,0) [0.0|1.0] "" Vector__XXX
 SG_ S9_C12_V_Err : 57|1@0+ (1,0) [0.0|1.0] "" Vector__XXX
 SG_ S9_C12_V : 55|14@0+ (0.00015,2.3) [2.3|4.75745] "V" Vector__XXX
 SG_ S9_C11_V_type_Err : 40|1@0+ (1,0) [0.0|1.0] "" Vector__XXX
 SG_ S9_C11_V_Err : 41|1@0+ (1,0) [0.0|1.0] "" Vector__XXX
 SG_ S9_C11_V : 39|14@0+ (0.00015,2.3) [2.3|4.75745] "V" Vector__XXX
 SG_ S9_C10_V_type_Err : 24|1@0+ (1,0) [0.0|1.0] "" Vector__XXX
 SG_ S9_C10_V_Err : 25|1@0+ (1,0) [0.0|1.0] "" Vector__XXX
 SG_ S9_C10_V : 23|14@0+ (0.00015,2.3) [2.3|4.75745] "V" Vector__XXX
 SG_ S9_C9_V_type_Err : 8|1@0+ (1,0) [0.0|1.0] "" Vector__XXX
 SG_ S9_C9_V_Err : 9|1@0+ (1,0) [0.0|1.0] "" Vector__XXX
 SG_ S9_C9_V : 7|14@0+ (0.00015,2.3) [2.3|4.75745] "V" Vector__XXX

BO_ 291 S9_Volt_4: 8 Master
 SG_ S9_C16_V_type_Err : 56|1@0+ (1,0) [0.0|1.0] "" Vector__XXX
 SG_ S9_C16_V_Err : 57|1@0+ (1,0) [0.0|1.0] "" Vector__XXX
 SG_ S9_C16_V : 55|14@0+ (0.00015,2.3) [2.3|4.75745] "V" Vector__XXX
 SG_ S9_C15_V_type_Err : 40|1@0+ (1,0) [0.0|1.0] "" Vector__XXX
 SG_ S9_C15_V_Err : 41|1@0+ (1,0) [0.0|1.0] "" Vector__XXX
 SG_ S9_C15_V : 39|14@0+ (0.00015,2.3) [2.3|4.75745] "V" Vector__XXX
 SG_ S9_C14_V_type_Err : 24|1@0+ (1,0) [0.0|1.0] "" Vector__XXX
 SG_ S9_C14_V_Err : 25|1@0+ (1,0) [0.0|1.0] "" Vector__XXX
 SG_ S9_C14_V : 23|14@0+ (0.00015,2.3) [2.3|4.75745] "V" Vector__XXX
 SG_ S9_C13_V_type_Err : 8|1@0+ (1,0) [0.0|1.0] "" Vector__XXX
 SG_ S9_C13_V_Err : 9|1@0+ (1,0) [0.0|1.0] "" Vector__XXX
 SG_ S9_C13_V : 7|14@0+ (0.00015,2.3) [2.3|4.75745] "V" Vector__XXX

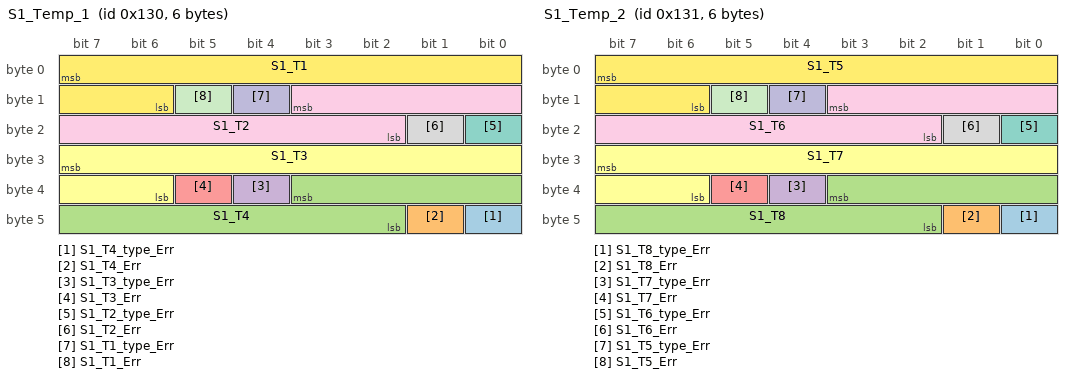
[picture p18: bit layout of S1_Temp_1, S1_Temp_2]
BO_ 304 S1_Temp_1: 6 Master
 SG_ S1_T4_type_Err : 40|1@0+ (1,0) [0.0|1.0] "" Vector__XXX
 SG_ S1_T4_Err : 41|1@0+ (1,0) [0.0|1.0] "" Vector__XXX
 SG_ S1_T4 : 35|10@0+ (0.1,0.0) [0.0|900.0] "°C" Vector__XXX
 SG_ S1_T3_type_Err : 36|1@0+ (1,0) [0.0|1.0] "" Vector__XXX
 SG_ S1_T3_Err : 37|1@0+ (1,0) [0.0|1.0] "" Vector__XXX
 SG_ S1_T3 : 31|10@0+ (0.1,0.0) [0.0|900.0] "°C" Vector__XXX
 SG_ S1_T2_type_Err : 16|1@0+ (1,0) [0.0|1.0] "" Vector__XXX
 SG_ S1_T2_Err : 17|1@0+ (1,0) [0.0|1.0] "" Vector__XXX
 SG_ S1_T2 : 11|10@0+ (0.1,0.0) [0.0|900.0] "°C" Vector__XXX
 SG_ S1_T1_type_Err : 12|1@0+ (1,0) [0.0|1.0] "" Vector__XXX
 SG_ S1_T1_Err : 13|1@0+ (1,0) [0.0|1.0] "" Vector__XXX
 SG_ S1_T1 : 7|10@0+ (0.1,0.0) [0.0|900.0] "°C" Vector__XXX

BO_ 305 S1_Temp_2: 6 Master
 SG_ S1_T8_type_Err : 40|1@0+ (1,0) [0.0|1.0] "" Vector__XXX
 SG_ S1_T8_Err : 41|1@0+ (1,0) [0.0|1.0] "" Vector__XXX
 SG_ S1_T8 : 35|10@0+ (0.1,0.0) [0.0|900.0] "°C" Vector__XXX
 SG_ S1_T7_type_Err : 36|1@0+ (1,0) [0.0|1.0] "" Vector__XXX
 SG_ S1_T7_Err : 37|1@0+ (1,0) [0.0|1.0] "" Vector__XXX
 SG_ S1_T7 : 31|10@0+ (0.1,0.0) [0.0|900.0] "°C" Vector__XXX
 SG_ S1_T6_type_Err : 16|1@0+ (1,0) [0.0|1.0] "" Vector__XXX
 SG_ S1_T6_Err : 17|1@0+ (1,0) [0.0|1.0] "" Vector__XXX
 SG_ S1_T6 : 11|10@0+ (0.1,0.0) [0.0|900.0] "°C" Vector__XXX
 SG_ S1_T5_type_Err : 12|1@0+ (1,0) [0.0|1.0] "" Vector__XXX
 SG_ S1_T5_Err : 13|1@0+ (1,0) [0.0|1.0] "" Vector__XXX
 SG_ S1_T5 : 7|10@0+ (0.1,0.0) [0.0|900.0] "°C" Vector__XXX

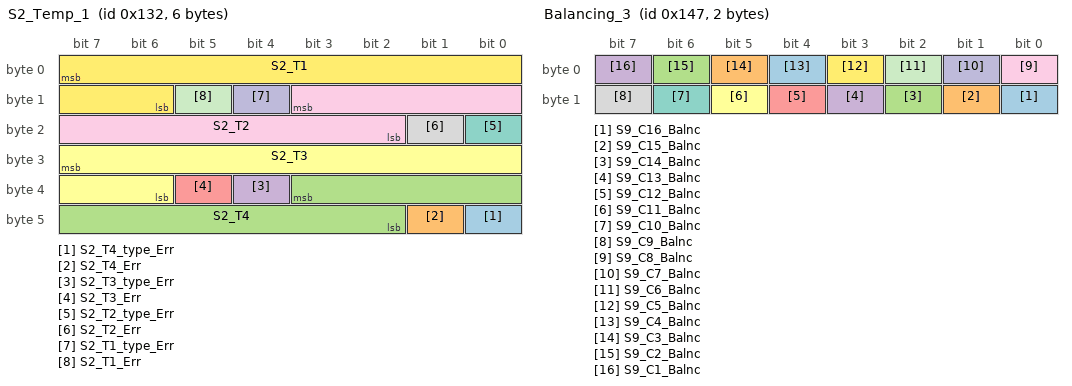
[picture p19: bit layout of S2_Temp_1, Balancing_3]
BO_ 306 S2_Temp_1: 6 Master
 SG_ S2_T4_type_Err : 40|1@0+ (1,0) [0.0|1.0] "" Vector__XXX
 SG_ S2_T4_Err : 41|1@0+ (1,0) [0.0|1.0] "" Vector__XXX
 SG_ S2_T4 : 35|10@0+ (0.1,0.0) [0.0|900.0] "°C" Vector__XXX
 SG_ S2_T3_type_Err : 36|1@0+ (1,0) [0.0|1.0] "" Vector__XXX
 SG_ S2_T3_Err : 37|1@0+ (1,0) [0.0|1.0] "" Vector__XXX
 SG_ S2_T3 : 31|10@0+ (0.1,0.0) [0.0|900.0] "°C" Vector__XXX
 SG_ S2_T2_type_Err : 16|1@0+ (1,0) [0.0|1.0] "" Vector__XXX
 SG_ S2_T2_Err : 17|1@0+ (1,0) [0.0|1.0] "" Vector__XXX
 SG_ S2_T2 : 11|10@0+ (0.1,0.0) [0.0|900.0] "°C" Vector__XXX
 SG_ S2_T1_type_Err : 12|1@0+ (1,0) [0.0|1.0] "" Vector__XXX
 SG_ S2_T1_Err : 13|1@0+ (1,0) [0.0|1.0] "" Vector__XXX
 SG_ S2_T1 : 7|10@0+ (0.1,0.0) [0.0|900.0] "°C" Vector__XXX

BO_ 307 S2_Temp_2: 6 Master
 SG_ S2_T8_type_Err : 40|1@0+ (1,0) [0.0|1.0] "" Vector__XXX
 SG_ S2_T8_Err : 41|1@0+ (1,0) [0.0|1.0] "" Vector__XXX
 SG_ S2_T8 : 35|10@0+ (0.1,0.0) [0.0|900.0] "°C" Vector__XXX
 SG_ S2_T7_type_Err : 36|1@0+ (1,0) [0.0|1.0] "" Vector__XXX
 SG_ S2_T7_Err : 37|1@0+ (1,0) [0.0|1.0] "" Vector__XXX
 SG_ S2_T7 : 31|10@0+ (0.1,0.0) [0.0|900.0] "°C" Vector__XXX
 SG_ S2_T6_type_Err : 16|1@0+ (1,0) [0.0|1.0] "" Vector__XXX
 SG_ S2_T6_Err : 17|1@0+ (1,0) [0.0|1.0] "" Vector__XXX
 SG_ S2_T6 : 11|10@0+ (0.1,0.0) [0.0|900.0] "°C" Vector__XXX
 SG_ S2_T5_type_Err : 12|1@0+ (1,0) [0.0|1.0] "" Vector__XXX
 SG_ S2_T5_Err : 13|1@0+ (1,0) [0.0|1.0] "" Vector__XXX
 SG_ S2_T5 : 7|10@0+ (0.1,0.0) [0.0|900.0] "°C" Vector__XXX

BO_ 308 S3_Temp_1: 6 Master
 SG_ S3_T4_type_Err : 40|1@0+ (1,0) [0.0|1.0] "" Vector__XXX
 SG_ S3_T4_Err : 41|1@0+ (1,0) [0.0|1.0] "" Vector__XXX
 SG_ S3_T4 : 35|10@0+ (0.1,0.0) [0.0|900.0] "°C" Vector__XXX
 SG_ S3_T3_type_Err : 36|1@0+ (1,0) [0.0|1.0] "" Vector__XXX
 SG_ S3_T3_Err : 37|1@0+ (1,0) [0.0|1.0] "" Vector__XXX
 SG_ S3_T3 : 31|10@0+ (0.1,0.0) [0.0|900.0] "°C" Vector__XXX
 SG_ S3_T2_type_Err : 16|1@0+ (1,0) [0.0|1.0] "" Vector__XXX
 SG_ S3_T2_Err : 17|1@0+ (1,0) [0.0|1.0] "" Vector__XXX
 SG_ S3_T2 : 11|10@0+ (0.1,0.0) [0.0|900.0] "°C" Vector__XXX
 SG_ S3_T1_type_Err : 12|1@0+ (1,0) [0.0|1.0] "" Vector__XXX
 SG_ S3_T1_Err : 13|1@0+ (1,0) [0.0|1.0] "" Vector__XXX
 SG_ S3_T1 : 7|10@0+ (0.1,0.0) [0.0|900.0] "°C" Vector__XXX

BO_ 309 S3_Temp_2: 6 Master
 SG_ S3_T8_type_Err : 40|1@0+ (1,0) [0.0|1.0] "" Vector__XXX
 SG_ S3_T8_Err : 41|1@0+ (1,0) [0.0|1.0] "" Vector__XXX
 SG_ S3_T8 : 35|10@0+ (0.1,0.0) [0.0|900.0] "°C" Vector__XXX
 SG_ S3_T7_type_Err : 36|1@0+ (1,0) [0.0|1.0] "" Vector__XXX
 SG_ S3_T7_Err : 37|1@0+ (1,0) [0.0|1.0] "" Vector__XXX
 SG_ S3_T7 : 31|10@0+ (0.1,0.0) [0.0|900.0] "°C" Vector__XXX
 SG_ S3_T6_type_Err : 16|1@0+ (1,0) [0.0|1.0] "" Vector__XXX
 SG_ S3_T6_Err : 17|1@0+ (1,0) [0.0|1.0] "" Vector__XXX
 SG_ S3_T6 : 11|10@0+ (0.1,0.0) [0.0|900.0] "°C" Vector__XXX
 SG_ S3_T5_type_Err : 12|1@0+ (1,0) [0.0|1.0] "" Vector__XXX
 SG_ S3_T5_Err : 13|1@0+ (1,0) [0.0|1.0] "" Vector__XXX
 SG_ S3_T5 : 7|10@0+ (0.1,0.0) [0.0|900.0] "°C" Vector__XXX

BO_ 310 S4_Temp_1: 6 Master
 SG_ S4_T4_type_Err : 40|1@0+ (1,0) [0.0|1.0] "" Vector__XXX
 SG_ S4_T4_Err : 41|1@0+ (1,0) [0.0|1.0] "" Vector__XXX
 SG_ S4_T4 : 35|10@0+ (0.1,0.0) [0.0|900.0] "°C" Vector__XXX
 SG_ S4_T3_type_Err : 36|1@0+ (1,0) [0.0|1.0] "" Vector__XXX
 SG_ S4_T3_Err : 37|1@0+ (1,0) [0.0|1.0] "" Vector__XXX
 SG_ S4_T3 : 31|10@0+ (0.1,0.0) [0.0|900.0] "°C" Vector__XXX
 SG_ S4_T2_type_Err : 16|1@0+ (1,0) [0.0|1.0] "" Vector__XXX
 SG_ S4_T2_Err : 17|1@0+ (1,0) [0.0|1.0] "" Vector__XXX
 SG_ S4_T2 : 11|10@0+ (0.1,0.0) [0.0|900.0] "°C" Vector__XXX
 SG_ S4_T1_type_Err : 12|1@0+ (1,0) [0.0|1.0] "" Vector__XXX
 SG_ S4_T1_Err : 13|1@0+ (1,0) [0.0|1.0] "" Vector__XXX
 SG_ S4_T1 : 7|10@0+ (0.1,0.0) [0.0|900.0] "°C" Vector__XXX

BO_ 311 S4_Temp_2: 6 Master
 SG_ S4_T8_type_Err : 40|1@0+ (1,0) [0.0|1.0] "" Vector__XXX
 SG_ S4_T8_Err : 41|1@0+ (1,0) [0.0|1.0] "" Vector__XXX
 SG_ S4_T8 : 35|10@0+ (0.1,0.0) [0.0|900.0] "°C" Vector__XXX
 SG_ S4_T7_type_Err : 36|1@0+ (1,0) [0.0|1.0] "" Vector__XXX
 SG_ S4_T7_Err : 37|1@0+ (1,0) [0.0|1.0] "" Vector__XXX
 SG_ S4_T7 : 31|10@0+ (0.1,0.0) [0.0|900.0] "°C" Vector__XXX
 SG_ S4_T6_type_Err : 16|1@0+ (1,0) [0.0|1.0] "" Vector__XXX
 SG_ S4_T6_Err : 17|1@0+ (1,0) [0.0|1.0] "" Vector__XXX
 SG_ S4_T6 : 11|10@0+ (0.1,0.0) [0.0|900.0] "°C" Vector__XXX
 SG_ S4_T5_type_Err : 12|1@0+ (1,0) [0.0|1.0] "" Vector__XXX
 SG_ S4_T5_Err : 13|1@0+ (1,0) [0.0|1.0] "" Vector__XXX
 SG_ S4_T5 : 7|10@0+ (0.1,0.0) [0.0|900.0] "°C" Vector__XXX

BO_ 312 S5_Temp_1: 6 Master
 SG_ S5_T4_type_Err : 40|1@0+ (1,0) [0.0|1.0] "" Vector__XXX
 SG_ S5_T4_Err : 41|1@0+ (1,0) [0.0|1.0] "" Vector__XXX
 SG_ S5_T4 : 35|10@0+ (0.1,0.0) [0.0|900.0] "°C" Vector__XXX
 SG_ S5_T3_type_Err : 36|1@0+ (1,0) [0.0|1.0] "" Vector__XXX
 SG_ S5_T3_Err : 37|1@0+ (1,0) [0.0|1.0] "" Vector__XXX
 SG_ S5_T3 : 31|10@0+ (0.1,0.0) [0.0|900.0] "°C" Vector__XXX
 SG_ S5_T2_type_Err : 16|1@0+ (1,0) [0.0|1.0] "" Vector__XXX
 SG_ S5_T2_Err : 17|1@0+ (1,0) [0.0|1.0] "" Vector__XXX
 SG_ S5_T2 : 11|10@0+ (0.1,0.0) [0.0|900.0] "°C" Vector__XXX
 SG_ S5_T1_type_Err : 12|1@0+ (1,0) [0.0|1.0] "" Vector__XXX
 SG_ S5_T1_Err : 13|1@0+ (1,0) [0.0|1.0] "" Vector__XXX
 SG_ S5_T1 : 7|10@0+ (0.1,0.0) [0.0|900.0] "°C" Vector__XXX

BO_ 313 S5_Temp_2: 6 Master
 SG_ S5_T8_type_Err : 40|1@0+ (1,0) [0.0|1.0] "" Vector__XXX
 SG_ S5_T8_Err : 41|1@0+ (1,0) [0.0|1.0] "" Vector__XXX
 SG_ S5_T8 : 35|10@0+ (0.1,0.0) [0.0|900.0] "°C" Vector__XXX
 SG_ S5_T7_type_Err : 36|1@0+ (1,0) [0.0|1.0] "" Vector__XXX
 SG_ S5_T7_Err : 37|1@0+ (1,0) [0.0|1.0] "" Vector__XXX
 SG_ S5_T7 : 31|10@0+ (0.1,0.0) [0.0|900.0] "°C" Vector__XXX
 SG_ S5_T6_type_Err : 16|1@0+ (1,0) [0.0|1.0] "" Vector__XXX
 SG_ S5_T6_Err : 17|1@0+ (1,0) [0.0|1.0] "" Vector__XXX
 SG_ S5_T6 : 11|10@0+ (0.1,0.0) [0.0|900.0] "°C" Vector__XXX
 SG_ S5_T5_type_Err : 12|1@0+ (1,0) [0.0|1.0] "" Vector__XXX
 SG_ S5_T5_Err : 13|1@0+ (1,0) [0.0|1.0] "" Vector__XXX
 SG_ S5_T5 : 7|10@0+ (0.1,0.0) [0.0|900.0] "°C" Vector__XXX

BO_ 314 S6_Temp_1: 6 Master
 SG_ S6_T4_type_Err : 40|1@0+ (1,0) [0.0|1.0] "" Vector__XXX
 SG_ S6_T4_Err : 41|1@0+ (1,0) [0.0|1.0] "" Vector__XXX
 SG_ S6_T4 : 35|10@0+ (0.1,0.0) [0.0|900.0] "°C" Vector__XXX
 SG_ S6_T3_type_Err : 36|1@0+ (1,0) [0.0|1.0] "" Vector__XXX
 SG_ S6_T3_Err : 37|1@0+ (1,0) [0.0|1.0] "" Vector__XXX
 SG_ S6_T3 : 31|10@0+ (0.1,0.0) [0.0|900.0] "°C" Vector__XXX
 SG_ S6_T2_type_Err : 16|1@0+ (1,0) [0.0|1.0] "" Vector__XXX
 SG_ S6_T2_Err : 17|1@0+ (1,0) [0.0|1.0] "" Vector__XXX
 SG_ S6_T2 : 11|10@0+ (0.1,0.0) [0.0|900.0] "°C" Vector__XXX
 SG_ S6_T1_type_Err : 12|1@0+ (1,0) [0.0|1.0] "" Vector__XXX
 SG_ S6_T1_Err : 13|1@0+ (1,0) [0.0|1.0] "" Vector__XXX
 SG_ S6_T1 : 7|10@0+ (0.1,0.0) [0.0|900.0] "°C" Vector__XXX

BO_ 315 S6_Temp_2: 6 Master
 SG_ S6_T8_type_Err : 40|1@0+ (1,0) [0.0|1.0] "" Vector__XXX
 SG_ S6_T8_Err : 41|1@0+ (1,0) [0.0|1.0] "" Vector__XXX
 SG_ S6_T8 : 35|10@0+ (0.1,0.0) [0.0|900.0] "°C" Vector__XXX
 SG_ S6_T7_type_Err : 36|1@0+ (1,0) [0.0|1.0] "" Vector__XXX
 SG_ S6_T7_Err : 37|1@0+ (1,0) [0.0|1.0] "" Vector__XXX
 SG_ S6_T7 : 31|10@0+ (0.1,0.0) [0.0|900.0] "°C" Vector__XXX
 SG_ S6_T6_type_Err : 16|1@0+ (1,0) [0.0|1.0] "" Vector__XXX
 SG_ S6_T6_Err : 17|1@0+ (1,0) [0.0|1.0] "" Vector__XXX
 SG_ S6_T6 : 11|10@0+ (0.1,0.0) [0.0|900.0] "°C" Vector__XXX
 SG_ S6_T5_type_Err : 12|1@0+ (1,0) [0.0|1.0] "" Vector__XXX
 SG_ S6_T5_Err : 13|1@0+ (1,0) [0.0|1.0] "" Vector__XXX
 SG_ S6_T5 : 7|10@0+ (0.1,0.0) [0.0|900.0] "°C" Vector__XXX

BO_ 316 S7_Temp_1: 6 Master
 SG_ S7_T4_type_Err : 40|1@0+ (1,0) [0.0|1.0] "" Vector__XXX
 SG_ S7_T4_Err : 41|1@0+ (1,0) [0.0|1.0] "" Vector__XXX
 SG_ S7_T4 : 35|10@0+ (0.1,0.0) [0.0|900.0] "°C" Vector__XXX
 SG_ S7_T3_type_Err : 36|1@0+ (1,0) [0.0|1.0] "" Vector__XXX
 SG_ S7_T3_Err : 37|1@0+ (1,0) [0.0|1.0] "" Vector__XXX
 SG_ S7_T3 : 31|10@0+ (0.1,0.0) [0.0|900.0] "°C" Vector__XXX
 SG_ S7_T2_type_Err : 16|1@0+ (1,0) [0.0|1.0] "" Vector__XXX
 SG_ S7_T2_Err : 17|1@0+ (1,0) [0.0|1.0] "" Vector__XXX
 SG_ S7_T2 : 11|10@0+ (0.1,0.0) [0.0|900.0] "°C" Vector__XXX
 SG_ S7_T1_type_Err : 12|1@0+ (1,0) [0.0|1.0] "" Vector__XXX
 SG_ S7_T1_Err : 13|1@0+ (1,0) [0.0|1.0] "" Vector__XXX
 SG_ S7_T1 : 7|10@0+ (0.1,0.0) [0.0|900.0] "°C" Vector__XXX

BO_ 317 S7_Temp_2: 6 Master
 SG_ S7_T8_type_Err : 40|1@0+ (1,0) [0.0|1.0] "" Vector__XXX
 SG_ S7_T8_Err : 41|1@0+ (1,0) [0.0|1.0] "" Vector__XXX
 SG_ S7_T8 : 35|10@0+ (0.1,0.0) [0.0|900.0] "°C" Vector__XXX
 SG_ S7_T7_type_Err : 36|1@0+ (1,0) [0.0|1.0] "" Vector__XXX
 SG_ S7_T7_Err : 37|1@0+ (1,0) [0.0|1.0] "" Vector__XXX
 SG_ S7_T7 : 31|10@0+ (0.1,0.0) [0.0|900.0] "°C" Vector__XXX
 SG_ S7_T6_type_Err : 16|1@0+ (1,0) [0.0|1.0] "" Vector__XXX
 SG_ S7_T6_Err : 17|1@0+ (1,0) [0.0|1.0] "" Vector__XXX
 SG_ S7_T6 : 11|10@0+ (0.1,0.0) [0.0|900.0] "°C" Vector__XXX
 SG_ S7_T5_type_Err : 12|1@0+ (1,0) [0.0|1.0] "" Vector__XXX
 SG_ S7_T5_Err : 13|1@0+ (1,0) [0.0|1.0] "" Vector__XXX
 SG_ S7_T5 : 7|10@0+ (0.1,0.0) [0.0|900.0] "°C" Vector__XXX

BO_ 318 S8_Temp_1: 6 Master
 SG_ S8_T4_type_Err : 40|1@0+ (1,0) [0.0|1.0] "" Vector__XXX
 SG_ S8_T4_Err : 41|1@0+ (1,0) [0.0|1.0] "" Vector__XXX
 SG_ S8_T4 : 35|10@0+ (0.1,0.0) [0.0|900.0] "°C" Vector__XXX
 SG_ S8_T3_type_Err : 36|1@0+ (1,0) [0.0|1.0] "" Vector__XXX
 SG_ S8_T3_Err : 37|1@0+ (1,0) [0.0|1.0] "" Vector__XXX
 SG_ S8_T3 : 31|10@0+ (0.1,0.0) [0.0|900.0] "°C" Vector__XXX
 SG_ S8_T2_type_Err : 16|1@0+ (1,0) [0.0|1.0] "" Vector__XXX
 SG_ S8_T2_Err : 17|1@0+ (1,0) [0.0|1.0] "" Vector__XXX
 SG_ S8_T2 : 11|10@0+ (0.1,0.0) [0.0|900.0] "°C" Vector__XXX
 SG_ S8_T1_type_Err : 12|1@0+ (1,0) [0.0|1.0] "" Vector__XXX
 SG_ S8_T1_Err : 13|1@0+ (1,0) [0.0|1.0] "" Vector__XXX
 SG_ S8_T1 : 7|10@0+ (0.1,0.0) [0.0|900.0] "°C" Vector__XXX

BO_ 319 S8_Temp_2: 6 Master
 SG_ S8_T8_type_Err : 40|1@0+ (1,0) [0.0|1.0] "" Vector__XXX
 SG_ S8_T8_Err : 41|1@0+ (1,0) [0.0|1.0] "" Vector__XXX
 SG_ S8_T8 : 35|10@0+ (0.1,0.0) [0.0|900.0] "°C" Vector__XXX
 SG_ S8_T7_type_Err : 36|1@0+ (1,0) [0.0|1.0] "" Vector__XXX
 SG_ S8_T7_Err : 37|1@0+ (1,0) [0.0|1.0] "" Vector__XXX
 SG_ S8_T7 : 31|10@0+ (0.1,0.0) [0.0|900.0] "°C" Vector__XXX
 SG_ S8_T6_type_Err : 16|1@0+ (1,0) [0.0|1.0] "" Vector__XXX
 SG_ S8_T6_Err : 17|1@0+ (1,0) [0.0|1.0] "" Vector__XXX
 SG_ S8_T6 : 11|10@0+ (0.1,0.0) [0.0|900.0] "°C" Vector__XXX
 SG_ S8_T5_type_Err : 12|1@0+ (1,0) [0.0|1.0] "" Vector__XXX
 SG_ S8_T5_Err : 13|1@0+ (1,0) [0.0|1.0] "" Vector__XXX
 SG_ S8_T5 : 7|10@0+ (0.1,0.0) [0.0|900.0] "°C" Vector__XXX

BO_ 320 S9_Temp_1: 6 Master
 SG_ S9_T4_type_Err : 40|1@0+ (1,0) [0.0|1.0] "" Vector__XXX
 SG_ S9_T4_Err : 41|1@0+ (1,0) [0.0|1.0] "" Vector__XXX
 SG_ S9_T4 : 35|10@0+ (0.1,0.0) [0.0|900.0] "°C" Vector__XXX
 SG_ S9_T3_type_Err : 36|1@0+ (1,0) [0.0|1.0] "" Vector__XXX
 SG_ S9_T3_Err : 37|1@0+ (1,0) [0.0|1.0] "" Vector__XXX
 SG_ S9_T3 : 31|10@0+ (0.1,0.0) [0.0|900.0] "°C" Vector__XXX
 SG_ S9_T2_type_Err : 16|1@0+ (1,0) [0.0|1.0] "" Vector__XXX
 SG_ S9_T2_Err : 17|1@0+ (1,0) [0.0|1.0] "" Vector__XXX
 SG_ S9_T2 : 11|10@0+ (0.1,0.0) [0.0|900.0] "°C" Vector__XXX
 SG_ S9_T1_type_Err : 12|1@0+ (1,0) [0.0|1.0] "" Vector__XXX
 SG_ S9_T1_Err : 13|1@0+ (1,0) [0.0|1.0] "" Vector__XXX
 SG_ S9_T1 : 7|10@0+ (0.1,0.0) [0.0|900.0] "°C" Vector__XXX

BO_ 321 S9_Temp_2: 6 Master
 SG_ S9_T8_type_Err : 40|1@0+ (1,0) [0.0|1.0] "" Vector__XXX
 SG_ S9_T8_Err : 41|1@0+ (1,0) [0.0|1.0] "" Vector__XXX
 SG_ S9_T8 : 35|10@0+ (0.1,0.0) [0.0|900.0] "°C" Vector__XXX
 SG_ S9_T7_type_Err : 36|1@0+ (1,0) [0.0|1.0] "" Vector__XXX
 SG_ S9_T7_Err : 37|1@0+ (1,0) [0.0|1.0] "" Vector__XXX
 SG_ S9_T7 : 31|10@0+ (0.1,0.0) [0.0|900.0] "°C" Vector__XXX
 SG_ S9_T6_type_Err : 16|1@0+ (1,0) [0.0|1.0] "" Vector__XXX
 SG_ S9_T6_Err : 17|1@0+ (1,0) [0.0|1.0] "" Vector__XXX
 SG_ S9_T6 : 11|10@0+ (0.1,0.0) [0.0|900.0] "°C" Vector__XXX
 SG_ S9_T5_type_Err : 12|1@0+ (1,0) [0.0|1.0] "" Vector__XXX
 SG_ S9_T5_Err : 13|1@0+ (1,0) [0.0|1.0] "" Vector__XXX
 SG_ S9_T5 : 7|10@0+ (0.1,0.0) [0.0|900.0] "°C" Vector__XXX

BO_ 325 Balancing_1: 8 Master
 SG_ S4_C16_Balnc : 56|1@0+ (1,0) [0.0|1.0] "" Vector__XXX
 SG_ S4_C15_Balnc : 57|1@0+ (1,0) [0.0|1.0] "" Vector__XXX
 SG_ S4_C14_Balnc : 58|1@0+ (1,0) [0.0|1.0] "" Vector__XXX
 SG_ S4_C13_Balnc : 59|1@0+ (1,0) [0.0|1.0] "" Vector__XXX
 SG_ S4_C12_Balnc : 60|1@0+ (1,0) [0.0|1.0] "" Vector__XXX
 SG_ S4_C11_Balnc : 61|1@0+ (1,0) [0.0|1.0] "" Vector__XXX
 SG_ S4_C10_Balnc : 62|1@0+ (1,0) [0.0|1.0] "" Vector__XXX
 SG_ S4_C9_Balnc : 63|1@0+ (1,0) [0.0|1.0] "" Vector__XXX
 SG_ S4_C8_Balnc : 48|1@0+ (1,0) [0.0|1.0] "" Vector__XXX
 SG_ S4_C7_Balnc : 49|1@0+ (1,0) [0.0|1.0] "" Vector__XXX
 SG_ S4_C6_Balnc : 50|1@0+ (1,0) [0.0|1.0] "" Vector__XXX
 SG_ S4_C5_Balnc : 51|1@0+ (1,0) [0.0|1.0] "" Vector__XXX
 SG_ S4_C4_Balnc : 52|1@0+ (1,0) [0.0|1.0] "" Vector__XXX
 SG_ S4_C3_Balnc : 53|1@0+ (1,0) [0.0|1.0] "" Vector__XXX
 SG_ S4_C2_Balnc : 54|1@0+ (1,0) [0.0|1.0] "" Vector__XXX
 SG_ S4_C1_Balnc : 55|1@0+ (1,0) [0.0|1.0] "" Vector__XXX
 SG_ S3_C16_Balnc : 40|1@0+ (1,0) [0.0|1.0] "" Vector__XXX
 SG_ S3_C15_Balnc : 41|1@0+ (1,0) [0.0|1.0] "" Vector__XXX
 SG_ S3_C14_Balnc : 42|1@0+ (1,0) [0.0|1.0] "" Vector__XXX
 SG_ S3_C13_Balnc : 43|1@0+ (1,0) [0.0|1.0] "" Vector__XXX
 SG_ S3_C12_Balnc : 44|1@0+ (1,0) [0.0|1.0] "" Vector__XXX
 SG_ S3_C11_Balnc : 45|1@0+ (1,0) [0.0|1.0] "" Vector__XXX
 SG_ S3_C10_Balnc : 46|1@0+ (1,0) [0.0|1.0] "" Vector__XXX
 SG_ S3_C9_Balnc : 47|1@0+ (1,0) [0.0|1.0] "" Vector__XXX
 SG_ S3_C8_Balnc : 32|1@0+ (1,0) [0.0|1.0] "" Vector__XXX
 SG_ S3_C7_Balnc : 33|1@0+ (1,0) [0.0|1.0] "" Vector__XXX
 SG_ S3_C6_Balnc : 34|1@0+ (1,0) [0.0|1.0] "" Vector__XXX
 SG_ S3_C5_Balnc : 35|1@0+ (1,0) [0.0|1.0] "" Vector__XXX
 SG_ S3_C4_Balnc : 36|1@0+ (1,0) [0.0|1.0] "" Vector__XXX
 SG_ S3_C3_Balnc : 37|1@0+ (1,0) [0.0|1.0] "" Vector__XXX
 SG_ S3_C2_Balnc : 38|1@0+ (1,0) [0.0|1.0] "" Vector__XXX
 SG_ S3_C1_Balnc : 39|1@0+ (1,0) [0.0|1.0] "" Vector__XXX
 SG_ S2_C16_Balnc : 24|1@0+ (1,0) [0.0|1.0] "" Vector__XXX
 SG_ S2_C15_Balnc : 25|1@0+ (1,0) [0.0|1.0] "" Vector__XXX
 SG_ S2_C14_Balnc : 26|1@0+ (1,0) [0.0|1.0] "" Vector__XXX
 SG_ S2_C13_Balnc : 27|1@0+ (1,0) [0.0|1.0] "" Vector__XXX
 SG_ S2_C12_Balnc : 28|1@0+ (1,0) [0.0|1.0] "" Vector__XXX
 SG_ S2_C11_Balnc : 29|1@0+ (1,0) [0.0|1.0] "" Vector__XXX
 SG_ S2_C10_Balnc : 30|1@0+ (1,0) [0.0|1.0] "" Vector__XXX
 SG_ S2_C9_Balnc : 31|1@0+ (1,0) [0.0|1.0] "" Vector__XXX
 SG_ S2_C8_Balnc : 16|1@0+ (1,0) [0.0|1.0] "" Vector__XXX
 SG_ S2_C7_Balnc : 17|1@0+ (1,0) [0.0|1.0] "" Vector__XXX
 SG_ S2_C6_Balnc : 18|1@0+ (1,0) [0.0|1.0] "" Vector__XXX
 SG_ S2_C5_Balnc : 19|1@0+ (1,0) [0.0|1.0] "" Vector__XXX
 SG_ S2_C4_Balnc : 20|1@0+ (1,0) [0.0|1.0] "" Vector__XXX
 SG_ S2_C3_Balnc : 21|1@0+ (1,0) [0.0|1.0] "" Vector__XXX
 SG_ S2_C2_Balnc : 22|1@0+ (1,0) [0.0|1.0] "" Vector__XXX
 SG_ S2_C1_Balnc : 23|1@0+ (1,0) [0.0|1.0] "" Vector__XXX
 SG_ S1_C16_Balnc : 8|1@0+ (1,0) [0.0|1.0] "" Vector__XXX
 SG_ S1_C15_Balnc : 9|1@0+ (1,0) [0.0|1.0] "" Vector__XXX
 SG_ S1_C14_Balnc : 10|1@0+ (1,0) [0.0|1.0] "" Vector__XXX
 SG_ S1_C13_Balnc : 11|1@0+ (1,0) [0.0|1.0] "" Vector__XXX
 SG_ S1_C12_Balnc : 12|1@0+ (1,0) [0.0|1.0] "" Vector__XXX
 SG_ S1_C11_Balnc : 13|1@0+ (1,0) [0.0|1.0] "" Vector__XXX
 SG_ S1_C10_Balnc : 14|1@0+ (1,0) [0.0|1.0] "" Vector__XXX
 SG_ S1_C9_Balnc : 15|1@0+ (1,0) [0.0|1.0] "" Vector__XXX
 SG_ S1_C8_Balnc : 0|1@0+ (1,0) [0.0|1.0] "" Vector__XXX
 SG_ S1_C7_Balnc : 1|1@0+ (1,0) [0.0|1.0] "" Vector__XXX
 SG_ S1_C6_Balnc : 2|1@0+ (1,0) [0.0|1.0] "" Vector__XXX
 SG_ S1_C5_Balnc : 3|1@0+ (1,0) [0.0|1.0] "" Vector__XXX
 SG_ S1_C4_Balnc : 4|1@0+ (1,0) [0.0|1.0] "" Vector__XXX
 SG_ S1_C3_Balnc : 5|1@0+ (1,0) [0.0|1.0] "" Vector__XXX
 SG_ S1_C2_Balnc : 6|1@0+ (1,0) [0.0|1.0] "" Vector__XXX
 SG_ S1_C1_Balnc : 7|1@0+ (1,0) [0.0|1.0] "" Vector__XXX

BO_ 326 Balancing_2: 8 Master
 SG_ S8_C16_Balnc : 56|1@0+ (1,0) [0.0|1.0] "" Vector__XXX
 SG_ S8_C15_Balnc : 57|1@0+ (1,0) [0.0|1.0] "" Vector__XXX
 SG_ S8_C14_Balnc : 58|1@0+ (1,0) [0.0|1.0] "" Vector__XXX
 SG_ S8_C13_Balnc : 59|1@0+ (1,0) [0.0|1.0] "" Vector__XXX
 SG_ S8_C12_Balnc : 60|1@0+ (1,0) [0.0|1.0] "" Vector__XXX
 SG_ S8_C11_Balnc : 61|1@0+ (1,0) [0.0|1.0] "" Vector__XXX
 SG_ S8_C10_Balnc : 62|1@0+ (1,0) [0.0|1.0] "" Vector__XXX
 SG_ S8_C9_Balnc : 63|1@0+ (1,0) [0.0|1.0] "" Vector__XXX
 SG_ S8_C8_Balnc : 48|1@0+ (1,0) [0.0|1.0] "" Vector__XXX
 SG_ S8_C7_Balnc : 49|1@0+ (1,0) [0.0|1.0] "" Vector__XXX
 SG_ S8_C6_Balnc : 50|1@0+ (1,0) [0.0|1.0] "" Vector__XXX
 SG_ S8_C5_Balnc : 51|1@0+ (1,0) [0.0|1.0] "" Vector__XXX
 SG_ S8_C4_Balnc : 52|1@0+ (1,0) [0.0|1.0] "" Vector__XXX
 SG_ S8_C3_Balnc : 53|1@0+ (1,0) [0.0|1.0] "" Vector__XXX
 SG_ S8_C2_Balnc : 54|1@0+ (1,0) [0.0|1.0] "" Vector__XXX
 SG_ S8_C1_Balnc : 55|1@0+ (1,0) [0.0|1.0] "" Vector__XXX
 SG_ S7_C16_Balnc : 40|1@0+ (1,0) [0.0|1.0] "" Vector__XXX
 SG_ S7_C15_Balnc : 41|1@0+ (1,0) [0.0|1.0] "" Vector__XXX
 SG_ S7_C14_Balnc : 42|1@0+ (1,0) [0.0|1.0] "" Vector__XXX
 SG_ S7_C13_Balnc : 43|1@0+ (1,0) [0.0|1.0] "" Vector__XXX
 SG_ S7_C12_Balnc : 44|1@0+ (1,0) [0.0|1.0] "" Vector__XXX
 SG_ S7_C11_Balnc : 45|1@0+ (1,0) [0.0|1.0] "" Vector__XXX
 SG_ S7_C10_Balnc : 46|1@0+ (1,0) [0.0|1.0] "" Vector__XXX
 SG_ S7_C9_Balnc : 47|1@0+ (1,0) [0.0|1.0] "" Vector__XXX
 SG_ S7_C8_Balnc : 32|1@0+ (1,0) [0.0|1.0] "" Vector__XXX
 SG_ S7_C7_Balnc : 33|1@0+ (1,0) [0.0|1.0] "" Vector__XXX
 SG_ S7_C6_Balnc : 34|1@0+ (1,0) [0.0|1.0] "" Vector__XXX
 SG_ S7_C5_Balnc : 35|1@0+ (1,0) [0.0|1.0] "" Vector__XXX
 SG_ S7_C4_Balnc : 36|1@0+ (1,0) [0.0|1.0] "" Vector__XXX
 SG_ S7_C3_Balnc : 37|1@0+ (1,0) [0.0|1.0] "" Vector__XXX
 SG_ S7_C2_Balnc : 38|1@0+ (1,0) [0.0|1.0] "" Vector__XXX
 SG_ S7_C1_Balnc : 39|1@0+ (1,0) [0.0|1.0] "" Vector__XXX
 SG_ S6_C16_Balnc : 24|1@0+ (1,0) [0.0|1.0] "" Vector__XXX
 SG_ S6_C15_Balnc : 25|1@0+ (1,0) [0.0|1.0] "" Vector__XXX
 SG_ S6_C14_Balnc : 26|1@0+ (1,0) [0.0|1.0] "" Vector__XXX
 SG_ S6_C13_Balnc : 27|1@0+ (1,0) [0.0|1.0] "" Vector__XXX
 SG_ S6_C12_Balnc : 28|1@0+ (1,0) [0.0|1.0] "" Vector__XXX
 SG_ S6_C11_Balnc : 29|1@0+ (1,0) [0.0|1.0] "" Vector__XXX
 SG_ S6_C10_Balnc : 30|1@0+ (1,0) [0.0|1.0] "" Vector__XXX
 SG_ S6_C9_Balnc : 31|1@0+ (1,0) [0.0|1.0] "" Vector__XXX
 SG_ S6_C8_Balnc : 16|1@0+ (1,0) [0.0|1.0] "" Vector__XXX
 SG_ S6_C7_Balnc : 17|1@0+ (1,0) [0.0|1.0] "" Vector__XXX
 SG_ S6_C6_Balnc : 18|1@0+ (1,0) [0.0|1.0] "" Vector__XXX
 SG_ S6_C5_Balnc : 19|1@0+ (1,0) [0.0|1.0] "" Vector__XXX
 SG_ S6_C4_Balnc : 20|1@0+ (1,0) [0.0|1.0] "" Vector__XXX
 SG_ S6_C3_Balnc : 21|1@0+ (1,0) [0.0|1.0] "" Vector__XXX
 SG_ S6_C2_Balnc : 22|1@0+ (1,0) [0.0|1.0] "" Vector__XXX
 SG_ S6_C1_Balnc : 23|1@0+ (1,0) [0.0|1.0] "" Vector__XXX
 SG_ S5_C16_Balnc : 8|1@0+ (1,0) [0.0|1.0] "" Vector__XXX
 SG_ S5_C15_Balnc : 9|1@0+ (1,0) [0.0|1.0] "" Vector__XXX
 SG_ S5_C14_Balnc : 10|1@0+ (1,0) [0.0|1.0] "" Vector__XXX
 SG_ S5_C13_Balnc : 11|1@0+ (1,0) [0.0|1.0] "" Vector__XXX
 SG_ S5_C12_Balnc : 12|1@0+ (1,0) [0.0|1.0] "" Vector__XXX
 SG_ S5_C11_Balnc : 13|1@0+ (1,0) [0.0|1.0] "" Vector__XXX
 SG_ S5_C10_Balnc : 14|1@0+ (1,0) [0.0|1.0] "" Vector__XXX
 SG_ S5_C9_Balnc : 15|1@0+ (1,0) [0.0|1.0] "" Vector__XXX
 SG_ S5_C8_Balnc : 0|1@0+ (1,0) [0.0|1.0] "" Vector__XXX
 SG_ S5_C7_Balnc : 1|1@0+ (1,0) [0.0|1.0] "" Vector__XXX
 SG_ S5_C6_Balnc : 2|1@0+ (1,0) [0.0|1.0] "" Vector__XXX
 SG_ S5_C5_Balnc : 3|1@0+ (1,0) [0.0|1.0] "" Vector__XXX
 SG_ S5_C4_Balnc : 4|1@0+ (1,0) [0.0|1.0] "" Vector__XXX
 SG_ S5_C3_Balnc : 5|1@0+ (1,0) [0.0|1.0] "" Vector__XXX
 SG_ S5_C2_Balnc : 6|1@0+ (1,0) [0.0|1.0] "" Vector__XXX
 SG_ S5_C1_Balnc : 7|1@0+ (1,0) [0.0|1.0] "" Vector__XXX

BO_ 327 Balancing_3: 2 Master
 SG_ S9_C16_Balnc : 8|1@0+ (1,0) [0.0|1.0] "" Vector__XXX
 SG_ S9_C15_Balnc : 9|1@0+ (1,0) [0.0|1.0] "" Vector__XXX
 SG_ S9_C14_Balnc : 10|1@0+ (1,0) [0.0|1.0] "" Vector__XXX
 SG_ S9_C13_Balnc : 11|1@0+ (1,0) [0.0|1.0] "" Vector__XXX
 SG_ S9_C12_Balnc : 12|1@0+ (1,0) [0.0|1.0] "" Vector__XXX
 SG_ S9_C11_Balnc : 13|1@0+ (1,0) [0.0|1.0] "" Vector__XXX
 SG_ S9_C10_Balnc : 14|1@0+ (1,0) [0.0|1.0] "" Vector__XXX
 SG_ S9_C9_Balnc : 15|1@0+ (1,0) [0.0|1.0] "" Vector__XXX
 SG_ S9_C8_Balnc : 0|1@0+ (1,0) [0.0|1.0] "" Vector__XXX
 SG_ S9_C7_Balnc : 1|1@0+ (1,0) [0.0|1.0] "" Vector__XXX
 SG_ S9_C6_Balnc : 2|1@0+ (1,0) [0.0|1.0] "" Vector__XXX
 SG_ S9_C5_Balnc : 3|1@0+ (1,0) [0.0|1.0] "" Vector__XXX
 SG_ S9_C4_Balnc : 4|1@0+ (1,0) [0.0|1.0] "" Vector__XXX
 SG_ S9_C3_Balnc : 5|1@0+ (1,0) [0.0|1.0] "" Vector__XXX
 SG_ S9_C2_Balnc : 6|1@0+ (1,0) [0.0|1.0] "" Vector__XXX
 SG_ S9_C1_Balnc : 7|1@0+ (1,0) [0.0|1.0] "" Vector__XXX

BO_ 336 Balnc_message: 2 Canoe
 SG_ Balnc_error : 8|1@0+ (1,0) [0.0|1.0] "" Vector__XXX
 SG_ Balnc_pregunta : 9|1@0+ (1,0) [0.0|1.0] "" Vector__XXX
 SG_ V_Balnc : 7|14@0+ (0.00015,2.3) [2.3|4.75745] "V" Vector__XXX
